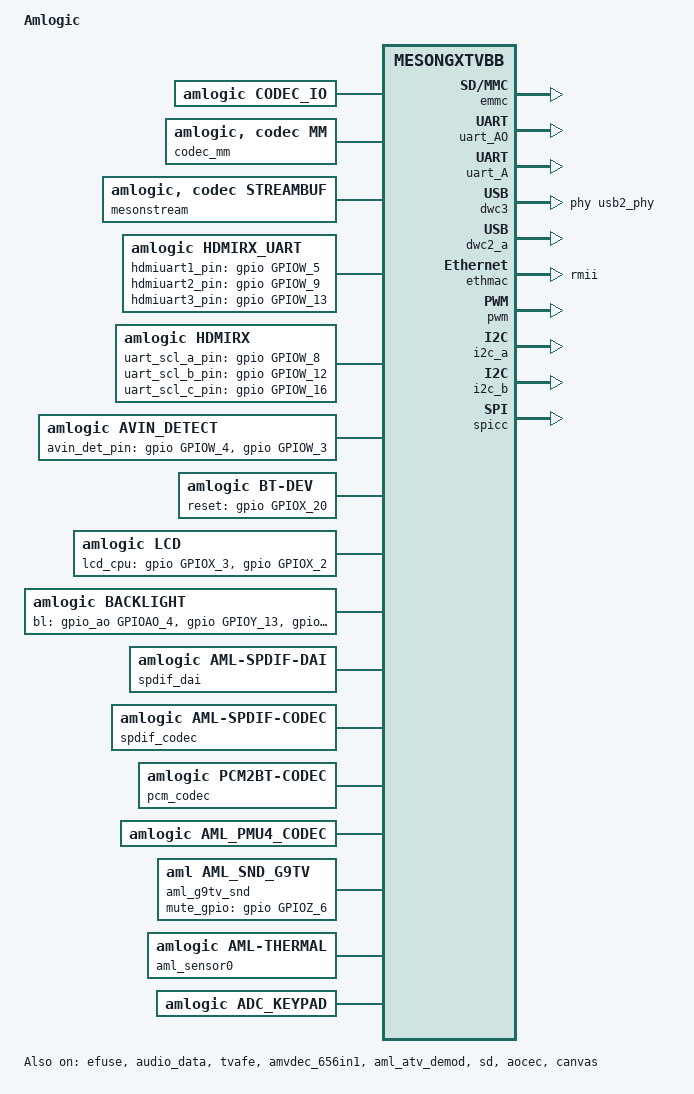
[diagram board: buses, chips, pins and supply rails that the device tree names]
/*
 * Amlogic Ltd. GXtvBaby Reference Plaform
 *
 */

/dts-v1/;

#include <dt-bindings/interrupt-controller/arm-gic.h>
#include <dt-bindings/clock/gxtvbb.h>
#include <dt-bindings/gpio/gxtvbb.h>
#include <dt-bindings/gpio/gpio.h>
#include <dt-bindings/reset/aml_gxtvbb.h>
#include "mesongxtvbb.dtsi"
#include <dt-bindings/pwm/pwm.h>
#include <dt-bindings/pwm/meson.h>

/ {
	model = "Amlogic";
	compatible = "amlogic, gxtvbb";
	interrupt-parent = <&gic>;
	#address-cells = <2>;
	#size-cells = <2>;

	aliases {
		serial0 = &uart_AO;
		serial1 = &uart_A;
	};

	memory@00000000 {
		device_type = "memory";
		linux,usable-memory = <0x0 0x1000000 0x0 0x3f000000>;
	};

	reserved-memory {
		#address-cells = <2>;
		#size-cells = <2>;
		ranges;
		/* global autoconfigured region for contiguous allocations */
		secmon_reserved:linux,secmon {
			compatible = "amlogic, aml_secmon_memory";
			reg = <0x0 0x10000000 0x0 0x200000>;
			no-map;
		};
		secos_reserved:linux,secos {
			status = "disable";
			compatible = "amlogic, aml_secos_memory";
			reg = <0x0 0x05300000 0x0 0x2000000>;
			no-map;
		};
		pstore:aml_pstore {
			compatible = "amlogic, pstore";
			reg = <0x0 0x07300000 0x0 0x100000>;
			no-map;
		};
		/*fb_reserved:linux,meson-fb {
			compatible = "amlogic, fb-memory";
			size = <0x0 0x2000000>;
			no-map;
		};*/
		/*di reserved mem*/
		di_reserved:linux,di {
			compatible = "amlogic, di-mem";
			/* buffer_size = 3552320(yuv422 8bit) | 4596800(yuv422 10bit) | 4074560(yuv422 10bit full pack mode) */
			/** 10x3552320=34M(0x22) support 8bit **/
			/** 10x44596800=44M(0x2c) support 12bit **/
			/** 10x4074560=39M(0x27) support 10bit **/
			size = <0x0 0x2c00000>;
			//no-map;
		};
		/*di CMA pool */
		//di_cma_reserved:linux,di_cma {
			//compatible = "shared-dma-pool";
			//reusable;
			/* buffer_size = 3552320(yuv422 8bit) | 44596800(yuv422 10bit) | 4074560(yuv422 10bit full pack mode) */
			/** 10x3552320=34M(0x22) support 8bit **/
			/** 10x44596800=44M(0x2c) support 12bit **/
			/** 10x4074560=39M(0x27) support 10bit **/
			//size = <0x0 0x03000000>;
			//alignment = <0x0 0x400000>;
		//};
		demod_reserved:linux,demod {
			compatible = "amlogic, demod-mem";
			size = <0x0 0x600000>; //20m
			multi-use;
			//no-map;
		};

		ion_reserved:linux,ion-dev {
			compatible = "amlogic, idev-mem";
			//size = <0x0 0x4000000>;
			/* the most significant 64M memory reserved for ion */
			reg = <0x0 0x3c000000 0x0 0x4000000>; /* for 1G memory */
			//reg = <0x0 0x5c000000 0x0 0x4000000>; /* for 1.5G memory*/
			//reg = <0x0 0x7c000000 0x0 0x4000000>; /* for 2G memory */
		};

		/*  POST PROCESS MANAGER */
		ppmgr_reserved:linux,ppmgr {
			compatible = "amlogic, ppmgr_memory";
			size = <0x0 0x0>;
			multi-use;
		};
/*
		amlvideo2_reserved:linux,amlvideo2 {
			compatible = "amlogic, amlvideo2_memory";
			size = <0x0 0x01800000>;
		};
*/
		codec_mm_cma:linux,codec_mm_cma {
			compatible = "shared-dma-pool";
			reusable;
			size = <0x0 0xc000000>;
			alignment = <0x0 0x400000>;
			linux,contiguous-region;
		};
		picdec_cma_reserved:linux,picdec {
			compatible = "shared-dma-pool";
			reusable;
			status = "disabled";
			size = <0x0 0x0>;
			alignment = <0x0 0x400000>;
			linux,contiguous-region;
		};
		/* codec shared reserved */
		codec_mm_reserved:linux,codec_mm_reserved {
			compatible = "amlogic, codec-mm-reserved";
			size = <0x0 0x4100000>;
			alignment = <0x0 0x100000>;
 			//no-map;
		};
		/*  vdin0 CMA pool */
		//vdin0_cma_reserved:linux,vdin0_cma {
		//	compatible = "shared-dma-pool";
		//	linux,phandle = <4>;
		//	reusable;
			/* 3840x2160x2x4  =64+4 M */
		//	size = <0x0 0x04400000>;
		//	alignment = <0x0 0x400000>;
		//};
		/*  vdin1 CMA pool */
		vdin1_cma_reserved:linux,vdin1_cma {
			compatible = "shared-dma-pool";
			linux,phandle = <5>;
			reusable;
			/* 1920x1080x2x4  =16+4 M */
			size = <0x0 0x01400000>;
			alignment = <0x0 0x400000>;
		};
		/*  tvafe CMA pool */
		//tvafe_cma_reserved:linux,tvafe_cma {
		//	compatible = "shared-dma-pool";
		//	linux,phandle = <6>;
		//	reusable;
			/* 5 M */
		//	size = <0x0 0x00800000>;
		//	alignment = <0x0 0x400000>;
		//};
	};

	meson-vout {
		compatible = "amlogic, meson-vout";
		dev_name = "meson-vout";
		status = "okay";
	};
	meson-fb {
		compatible = "amlogic, meson-fb";
		/*memory-region = <&fb_reserved>;*/
		dev_name = "meson-fb";
		status = "okay";
		interrupts = <0 3 1
			0 89 1>;
		interrupt-names = "viu-vsync", "rdma";
		mem_size = <0x01851000 0x00100000>; /* fb0/fb1 memory size */
		display_mode_default = "1080p60hz";
		scale_mode = <1>; /** 0:VPU free scale 1:OSD free scale 2:OSD super scale */
		// display_size_default: PAGE_ALIGN((1920*(align16(1080))/256*(256*16 + 16)+16)*3) =
		// 0x1848000 (afbc body + afbc header + 16)*3
		display_size_default = <1920 1080 1920 3240 32>;
		/*pxp_mode = <1>; /** 0:normal mode 1:pxp mode */
		logo_addr = "0x3d851000"; /*ion base + fb0 memory size for uboot logo osd1*/
	};
	ge2d {
		compatible = "amlogic, ge2d";
		dev_name = "ge2d";
		status = "okay";
		interrupts = <0 150 1>;
		interrupt-names = "ge2d";
		clocks = <&clock CLK_VAPB_0>,
			<&clock CLK_GE2D>;
		clock-names = "clk_vapb_0",
				"clk_ge2d";
		resets = <&clock GCLK_IDX_GE2D>;
		reset-names = "ge2d";
	};
	codec_io {
		compatible = "amlogic, codec_io";
		#address-cells=<2>;
		#size-cells=<2>;
		ranges;
		io_cbus_base{
			reg = <0x0 0xC0800000 0x0 0xb00000>;
		};
		io_dos_base{
			reg = <0x0 0xc8820000 0x0 0x10000>;
		};
		io_hiubus_base{
			reg = <0x0 0xc883c000 0x0 0x2000>;
		};
		io_aobus_base{
			reg = <0x0 0xc8100000 0x0 0x100000>;
		};
		io_vcbus_base{
			reg = <0x0 0xd0100000 0x0 0x40000>;
		};
		io_dmc_base{
			reg = <0x0 0xc8838000 0x0 0x2000>;
		};
	};
	codec_mm {
			compatible = "amlogic, codec, mm";
			memory-region = <&codec_mm_cma &codec_mm_reserved>;
			dev_name = "codec_mm";
			status = "okay";
	};

	mesonstream {
		compatible = "amlogic, codec, streambuf";
		dev_name = "mesonstream";
		status = "okay";
		resets = <&clock GCLK_IDX_HIU_PARSER_TOP
			&clock GCLK_IDX_VPU_INTR
			&clock GCLK_IDX_DEMUX
			&clock GCLK_IDX_DOS>;
		reset-names = "parser_top",
			"vpu_intr",
			"demux",
			"vdec";
	};

	amvideocap {
		compatible = "amlogic, amvideocap";
		dev_name = "amvideocap.0";
		status = "okay";
		max_size = <8>;//8M
	};

	ion_dev {
		compatible = "amlogic, ion_dev";
		memory-region = <&ion_reserved>;
	};

	vdec {
		compatible = "amlogic, vdec";
		dev_name = "vdec.0";
		status = "okay";
		interrupts = <0 3 1
			0 23 1
			0 32 1
			0 43 1
			0 44 1
			0 45 1>;
		interrupt-names = "vsync",
			"demux",
			"parser",
			"mailbox_0",
			"mailbox_1",
			"mailbox_2";
	};
	picdec {
		   compatible = "amlogic, picdec";
		   memory-region = <&picdec_cma_reserved>;
		   dev_name = "picdec";
		   status = "okay";
	};
	ppmgr {
		compatible = "amlogic, ppmgr";//to match of_device_id's compatible member
		memory-region = <&ppmgr_reserved>;
		dev_name = "ppmgr";
		status = "okay";
	};
	deinterlace {
		compatible = "amlogic, deinterlace";
		status = "okay";
		flag_cma = <0>;/*0:use reserved;1:use cma*/
		memory-region = <&di_reserved>;
		//memory-region = <&di_cma_reserved>;
		interrupts = <0 46 1
				0 6 1>;
		interrupt-names = "de_irq",
				"timerc";
		/* nr_size(byte) = 1920*544*2(yuv422 8bit) | 1920*544*2*12/8(yuv422 10bit) | 1920*544*2*10/8(yuv422 10bit full pack mode) */
		/* mtn_size(byte) = 1920*544/2 */
		/* count_size(byte) = 1920*544/2 */
		/* mv_size(byte) = 1920*544*2/5 */
		/* mc_size(byte) = 544*2 */
		/* buffer_size = nr_size + mtn_size + count_size + mv_size + mc_size */
		/* buffer_size = 3552320(yuv422 8bit) | 4596800(yuv422 10bit) | 4074560(yuv422 10bit full pack mode) */
		buffer-size = <4596800>;
		hw-version = <2>;
		/* reserve-iomap = "true"; */
		/* if enable nr10bit, set nr10bit-surpport to 1 */
		nr10bit-surpport = <1>;
	};
/*
	amlvideo2 {
		compatible = "amlogic, amlvideo2";
		memory-region = <&amlvideo2_reserved>;
		dev_name = "amlvideo2";
		status = "okay";
	};
*/
	vdin0 {
		compatible = "amlogic, vdin";
		/*memory-region = <&vdin0_cma_reserved>;*/
		dev_name = "vdin0";
		status = "ok";
		reserve-iomap = "true";
		flag_cma = <1>;/*1:share with codec_mm;2:cma alone*/
		/*MByte, if 10bit disable: 64M(YUV422), if 10bit enable: 64*1.5 = 96M(YUV422)
		*if support 4K2K-YUV444-10bit-WR:3840*2160*4*4 ~= 128M
		*if support 4K2K-YUV422-10bit-wr:3840*2160*3*4 ~= 96M
		*if support 4K2K-YUV422-8BIT-WR:3840*2160*2*4 ~= 64M
		*if support 1080p-YUV422-8BIT-WR:1920*1080*2*4 ~= 16M*/
		cma_size = <128>;
		interrupts = <0 83 1>;
		rdma-irq = <2>;
		clocks = <&clock CLK_FPLL_DIV5>,
			<&clock CLK_VDIN_MEAS_CLK>;
		clock-names = "fclk_div5", "cts_vdin_meas_clk";
		vdin_id = <0>;
		/*vdin write mem color depth support:
		*bit0:support 8bit
		*bit1:support 9bit
		*bit2:support 10bit
		*bit3:support 12bit*/
		tv_bit_mode = <5>;
	};
	vdin1 {
		compatible = "amlogic, vdin";
		memory-region = <&vdin1_cma_reserved>;
		dev_name = "vdin1";
		status = "ok";
		reserve-iomap = "true";
		flag_cma = <0>;/*1:share with codec_mm;0:cma alone*/
		interrupts = <0 85 1>;
		rdma-irq = <4>;
		clocks = <&clock CLK_FPLL_DIV5>,
			<&clock CLK_VDIN_MEAS_CLK>;
		clock-names = "fclk_div5", "cts_vdin_meas_clk";
		vdin_id = <1>;
		/*vdin write mem color depth support:
		*bit0:support 8bit
		*bit1:support 9bit
		*bit2:support 10bit
		*bit3:support 12bit*/
		tv_bit_mode = <1>;
	};
	hdmirx_uart {
		compatible = "amlogic, hdmirx_uart";
		status = "ok";
		pinctrl-names = "hdmirx_init_pin","hu_det_none",
				"hu_det_u1","hu_det_u2","hu_det_u3",
				"hu_det_h1","hu_det_h2","hu_det_h3",
				"hu_det_h1h2","hu_det_h1h3","hu_det_h2h3","hu_det_h1h2h3",
				"hu_det_u1_h2","hu_det_u1_h3","hu_det_u1_h2h3",
				"hu_det_u2_h1","hu_det_u2_h3","hu_det_u2_h1h3",
				"hu_det_u3_h1","hu_det_u3_h2","hu_det_u3_h1h2";
		pinctrl-0 = <&hdmirx_init_pin>;
		pinctrl-1 = <&hdmirx_init_pin &hu_hpds_gpio>;
		pinctrl-2 = <&hdmirx_init_pin &hu_hpds_gpio &u_ch1_in>;
		pinctrl-3 = <&hdmirx_init_pin &hu_hpds_gpio &u_ch2_in>;
		pinctrl-4 = <&hdmirx_init_pin &hu_hpds_gpio &u_ch3_in>;
		pinctrl-5 = <&hdmirx_init_pin &hu_hpd2_gpio &hu_hpd3_gpio>;
		pinctrl-6 = <&hdmirx_init_pin &hu_hpd1_gpio &hu_hpd3_gpio>;
		pinctrl-7 = <&hdmirx_init_pin &hu_hpd1_gpio &hu_hpd2_gpio>;
		pinctrl-8 = <&hdmirx_init_pin &hu_hpd3_gpio>;
		pinctrl-9 = <&hdmirx_init_pin &hu_hpd2_gpio>;
		pinctrl-10 = <&hdmirx_init_pin &hu_hpd1_gpio>;
		pinctrl-11 = <&hdmirx_init_pin &hu_uart_init>;
		pinctrl-12 = <&hdmirx_init_pin &hu_hpd1_gpio &hu_hpd3_gpio &u_ch1_in>;
		pinctrl-13 = <&hdmirx_init_pin &hu_hpd1_gpio &hu_hpd2_gpio &u_ch1_in>;
		pinctrl-14 = <&hdmirx_init_pin &hu_hpd1_gpio &u_ch1_in>;
		pinctrl-15 = <&hdmirx_init_pin &hu_hpd2_gpio &hu_hpd3_gpio &u_ch2_in>;
		pinctrl-16 = <&hdmirx_init_pin &hu_hpd1_gpio &hu_hpd2_gpio &u_ch2_in>;
		pinctrl-17 = <&hdmirx_init_pin &hu_hpd2_gpio &u_ch2_in>;
		pinctrl-18 = <&hdmirx_init_pin &hu_hpd2_gpio &hu_hpd3_gpio &u_ch3_in>;
		pinctrl-19 = <&hdmirx_init_pin &hu_hpd1_gpio &hu_hpd3_gpio &u_ch3_in>;
		pinctrl-20 = <&hdmirx_init_pin &hu_hpd3_gpio &u_ch3_in>;
		hdmiuart1_pin =  <&gpio       GPIOW_5       GPIO_ACTIVE_HIGH>;
		hdmiuart2_pin =  <&gpio       GPIOW_9       GPIO_ACTIVE_HIGH>;
		hdmiuart3_pin =  <&gpio       GPIOW_13      GPIO_ACTIVE_HIGH>;
		hdmiuart_use_num = <7>;/*0:dont use. 1:use num1. 2:use num2. 4:use num3*/
	};

	hdmirx {
		compatible = "amlogic, hdmirx";
		dev_name = "hdmirx";
		status = "ok";
		pinctrl-names = "hdmirx_pins","hu_det_none",
				"hu_det_uart0","hu_det_uart1","hu_det_uart2";
		pinctrl-0 = <&hdmirx_pins>;
		pinctrl-1 = <&hu_det_none>;
		pinctrl-2 = <&hdmirx_pins &cha_uart_in>;
		pinctrl-3 = <&hdmirx_pins &chb_uart_in>;
		pinctrl-4 = <&hdmirx_pins &chc_uart_in>;
		rx_port_maps = <0x3120>;
		hdmiuart_share_cfg = <0>;
		repeat = <0>;
		interrupts = <0 56 1>;
		hdmirx_addr_port = <0xda83e000>;
		hdmirx_data_port = <0xda83e004>;
		hdmirx_ctrl_port = <0xda83e008>;
		clocks = <&clock CLK_HDMIRX_MODET_CLK>,
			<&clock CLK_HDMIRX_CFG_CLK>,
			<&clock CLK_HDMIRX_ACR_REF_CLK>,
			<&clock CLK_HDMIRX_AUDMEAS_CLK>,
			<&clock CLK_XTAL>,
			<&clock CLK_FPLL_DIV5>;
		clock-names = "hdmirx_modet_clk",
			"hdmirx_cfg_clk",
			"hdmirx_acr_ref_clk",
			"hdmirx_audmeas_clk",
			"xtal",
			"fclk_div5";
		hdmirx_id = <0>;
		en_4k_2_2k = <0>;
		uart_scl_a_pin =  <&gpio       GPIOW_8       GPIO_ACTIVE_HIGH>;
		uart_scl_b_pin =  <&gpio       GPIOW_12      GPIO_ACTIVE_HIGH>;
		uart_scl_c_pin =  <&gpio       GPIOW_16      GPIO_ACTIVE_HIGH>;
 	};
	tvafe {
		compatible = "amlogic, tvafe";
		/*memory-region = <&tvafe_cma_reserved>;*/
		dev_name = "tvafe";
		status = "ok";
		flag_cma = <1>;/*1:share with codec_mm;0:cma alone*/
		cma_size = <5>;/*MByte*/
		reg = <0x0 0xc8842000 0x0 0x2000>;
		reserve-iomap = "true";
		tvafe_id = <0>;
		pinctrl-names = "default";
		tvafe_pin_mux = < /*!!particular sequence, no more and no less!!!*/
                        2       /*// TVAFE_CVBS_IN1,  //CVBS_IN0 = 0,*/
                        1       /*// TVAFE_CVBS_IN0,    //CVBS_IN1,*/
                        3       /*// TVAFE_CVBS_IN2,  //CVBS_IN2*/
                        4       /*// TVAFE_CVBS_IN3,    //CVBS_IN3,*/
		>;
	};
	avin_detect {
		compatible = "amlogic, avin_detect";
		status = "okay";
		avin_device_num = <2>;
		interrupts = <0 65 1
					  0 66 1>;
		pinctrl-names = "avin_gpio_disable_pullup";
		pinctrl-0 = <&avin_gpio_disable_pull>;
		avin_det_pin =  <&gpio       GPIOW_4       GPIO_ACTIVE_HIGH>,
						<&gpio       GPIOW_3       GPIO_ACTIVE_HIGH>;
		detect_interval_length = <100>;
		set_detect_times = <5>;
		set_fault_tolerance = <1>;
	};
	amvdec_656in1 {
		compatible = "amlogic, amvdec_656in";
		dev_name = "amvdec_656in1";
		status = "ok";
		reg = <0x0 0xd0050000 0x0 0x7c>;
		clocks = <&clock CLK_FPLL_DIV2>,
			<&clock CLK_BT656_CLK1>;
		clock-names = "fclk_div2", "cts_bt656_clk1";
		bt656_id = <1>;
	};
	dvb {
		compatible = "amlogic, dvb";
		dev_name = "dvb";
		status = "okay";
		/*"parallel","serial","disable"*/
		ts2 = "parallel";
		ts2_control = <0>;
		ts2_invert = <0>;
		resets = <&clock GCLK_IDX_DEMUX
				&clock GCLK_IDX_ASYNC_FIFO
				&clock GCLK_IDX_AHB_ARB0
				&clock GCLK_IDX_HIU_PARSER_TOP>;
		reset-names = "demux", "asyncfifo", "ahbarb0", "uparsertop";
	};
	dvbfe {
		compatible = "amlogic, dvbfe";
		dev_name = "dvbfe";
		status = "okay";
		dtv_demod0 = "AMLDEMOD";
		fe0_dtv_demod = <0>;
		fe0_ts = <2>;
		fe0_dev = <0>;
		dtv_demod0_mem = <0>;
		dtv_demod0_spectrum = <1>;
		memory-region = <&demod_reserved>;
		tuner0 = "r840_tuner";
		tuner0_i2c_adap_id = <1>;
		tuner0_i2c_addr = <0x74>;
		//tuner0_reset_value = <0>;
		//tuner0_reset_gpio =  "GPIOY_10" ;  /*GPIOX_8   76*/
		fe0_tuner = <0>;
		atv_demod0 = "aml_atv_demod";
		fe0_atv_demod = <0>;
	};
	aml_atv_demod {
		compatible = "amlogic, aml_atv_demod";
		dev_name = "aml_atv_demod";
		status = "okay";
		pinctrl-names="atvdemod_agc";
		pinctrl-0=<&atvdemod_agc>;
		reg = <0x0 0xc8840000 0x0 0x2000>;
		reg_23cf = <0x88188832>;/*default:0x88188832;r840 on haier:0x48188832*/
		audio_gain_val = <1024>; /*haier need this*/
		video_gain_val = <0x5C8808C1>;
	};
	amlvecm {
		compatible = "amlogic, vecm";
		dev_name = "aml_vecm";
		status = "okay";
		gamma_en = <1>;/*1:enabel ;0:disable*/
		wb_en = <1>;/*1:enabel ;0:disable*/
		cm_en = <1>;/*1:enabel ;0:disable*/
	};

	amvenc_avc{
		compatible = "amlogic, amvenc_avc";
		//memory-region = <&amvenc_avc_reserved>;
		//memory-region = <&avc_cma_reserved>;
		dev_name = "amvenc_avc";
		status = "okay";
		interrupts = <0 45 1>;
		interrupt-names = "mailbox_2";
	};



	vpu {
		compatible = "amlogic, vpu";
		dev_name = "vpu";
		status = "ok";
		clk_level = <7>;
		/**	0: 100.0M    1: 166.7M    2: 200.0M
			3: 250.0M    4: 333.3M    5: 400.0M
			6: 500.0M    7: 666.7M */
	};
	bt-dev{
		compatible = "amlogic, bt-dev";
		dev_name = "bt-dev";
		status = "ok";
		gpio_reset = <&gpio       GPIOX_20       GPIO_ACTIVE_HIGH>;
	};
	rtc {
		compatible = "amlogic, aml_vrtc";
		alarm_reg_addr = <0xc81000a8>;
		timer_e_addr = <0xc1109988>;
		init_date = "2015/01/01";
		status = "okay";
	};
	emmc{
		compatible = "amlogic, aml_sd_emmc";
		dev_name = "aml_newsd.0";
		status = "okay";
		reg = <0x0 0xd0074000 0x0 0x2000>;
		interrupts = <	0 218 1>;
		pinctrl-names = "emmc_clk_cmd_pins", "emmc_all_pins";
		pinctrl-0 = <&emmc_clk_cmd_pins>;
		pinctrl-1 = <&emmc_all_pins>;
		emmc{
			status = "okay";
			pinname = "emmc";
			ocr_avail = <0x200080>;          /**VDD voltage 3.3 ~ 3.4 */
			caps = "MMC_CAP_8_BIT_DATA","MMC_CAP_MMC_HIGHSPEED",
				 "MMC_CAP_SD_HIGHSPEED", "MMC_CAP_NONREMOVABLE", "MMC_CAP_1_8V_DDR",
				 "MMC_CAP_ERASE", "MMC_CAP_HW_RESET", "MMC_CAP_CMD23";
			caps2 = "MMC_CAP2_HS200";
			f_min = <300000>;
			f_max = <100000000>;
			tx_phase = <1>;
			max_req_size = <0x20000>;          /**256KB*/
			//            gpio_dat3 = "BOOT_3"
			gpio_dat3 = <&gpio       BOOT_3      GPIO_ACTIVE_HIGH>;
			hw_reset =  <&gpio       BOOT_9      GPIO_ACTIVE_HIGH>;
			card_type = <1>; /* 1:mmc card(include eMMC), 2:sd card(include tSD), */
		};
	};
    sd{
        compatible = "amlogic, aml_sd_emmc";
        dev_name = "aml_newsd.0";
        status = "okay";
        reg = <0x0 0xd0072000 0x0 0x2000>;
        interrupts = <	0 217 1
        				0 67 1
        				0 69 1>;
        pinctrl-names = "sd_clk_cmd_pins", "sd_all_pins";
        pinctrl-0 = <&sd_clk_cmd_pins>;
        pinctrl-1 = <&sd_all_pins>;
		sd{
	   		status = "okay";
	   		pinname = "sd";
	   		ocr_avail = <0x00200080>; // 3.3:0x200000, 1.8+3.3:0x00200080
	   		caps = "MMC_CAP_4_BIT_DATA","MMC_CAP_MMC_HIGHSPEED",
					"MMC_CAP_SD_HIGHSPEED";
	   				//,"MMC_CAP_UHS_SDR12",
	   				//"MMC_CAP_UHS_SDR25","MMC_CAP_UHS_SDR50",
	   				//"MMC_CAP_UHS_SDR104","MMC_CAP_NONREMOVABLE";
	   		f_min = <300000>;
	   		f_max = <100000000>;
	   		max_req_size = <0x20000>;          /**128KB*/
			gpio_dat3 = <&gpio       CARD_4       GPIO_ACTIVE_HIGH>;
			jtag_pin =  <&gpio       CARD_0       GPIO_ACTIVE_HIGH>;
			gpio_cd =  <&gpio       CARD_6       GPIO_ACTIVE_HIGH>;
			irq_in = <3>;
			irq_out = <5>;
	   		card_type = <5>; /* 0:unknown, 1:mmc card(include eMMC), 2:sd card(include tSD), 3:sdio device(ie:sdio-wifi), 4:SD combo (IO+mem) card, 5:NON sdio device(means sd/mmc card), other:reserved */
		};
    };

	nand{
		compatible = "amlogic, aml_nand";
		dev_name = "nand";
		status = "disabled";
		reg = <0x0 0xd0074800 0x0 0x200>;
		interrupts = <	0 34 1 >;
		pinctrl-names = "nand_rb_mod","nand_norb_mod", "nand_cs_pins_only";
		pinctrl-0 = <&conf_nand_pulldown &conf_nand_pullup &all_nand_pins>;
		pinctrl-1 = <&conf_nand_pulldown &conf_nand_pullup &all_nand_pins>;
		pinctrl-2 = <&nand_cs_pins>;
		device_id = <0>;
		plat-names = "nandnormal";
		plat-num = <1>;
		plat-part-0 = <&normal>;
		normal: normal{
			enable_pad ="ce0","ce1","ce2","ce3";
			busy_pad = "rb0";
		};
	};
	partitions: partitions{
        parts = <12>;
		part-0 = <&logo>;
		part-1 = <&recovery>;
		part-2 = <&param>;
		part-3 = <&tee>;
		part-4 = <&crypt>;
		part-5 = <&misc>;
		part-6 = <&instaboot>;
		part-7 = <&boot>;
		part-8 = <&system>;
		part-9 = <&cache>;
		part-10 = <&cri_data>;
		part-11 = <&data>;

		logo:logo{
			pname = "logo";
			size = <0x0 0x2000000>;
			mask = <1>;
		};
		recovery:recovery{
			pname = "recovery";
			size = <0x0 0x2000000>;
			mask = <1>;
		};
		param:param{
			pname = "param";
			size = <0x0 0x8000000>;
			mask = <2>;
		};
		tee:tee{
			pname = "tee";
			size = <0x0 0x800000>;
			mask = <1>;
		};
		crypt:crypt{
			pname = "crypt";
			size = <0x0 0x2000000>;
			mask = <1>;
		};
		misc:misc{
			pname = "misc";
			size = <0x0 0x2000000>;
			mask = <1>;
		};
		instaboot:instaboot{
			pname = "instaboot";
			size = <0x0 0x20000000>;
			mask = <1>;
		};
		boot:boot
		{
			pname = "boot";
			size = <0x0 0x2000000>;
			mask = <1>;
		};
		system:system
		{
			pname = "system";
			size = <0x0 0x40000000>;
			mask = <1>;
		};
		cache:cache
		{
			pname = "cache";
			size = <0x0 0x20000000>;
			mask = <2>;
		};
		cri_data:cri_data
		{
			pname = "cri_data";
			size = <0x0 0x1000000>;
			mask = <2>;
		};
		data:data
		{
			pname = "data";
			size = <0xffffffff 0xffffffff>;
			mask = <4>;
		};
	};
	unifykey{
		compatible = "amlogic, unifykey";
		status = "ok";

		unifykey-num = <14>;
		unifykey-index-0 = <&keysn_0>;
		unifykey-index-1 = <&keysn_1>;
		unifykey-index-2 = <&keysn_2>;
		unifykey-index-3 = <&keysn_3>;
		unifykey-index-4 = <&keysn_4>;
		unifykey-index-5 = <&keysn_5>;
		unifykey-index-6 = <&keysn_6>;
		unifykey-index-7 = <&keysn_7>;
		unifykey-index-8 = <&keysn_8>;
		unifykey-index-9 = <&keysn_9>;
		unifykey-index-10= <&keysn_10>;
		unifykey-index-11 = <&keysn_11>;
		unifykey-index-12 = <&keysn_12>;
		unifykey-index-13 = <&keysn_13>;

                keysn_0: key_0{
			key-name = "usid";
			key-device = "normal";
			key-permit = "read","write","del";
		};
		keysn_1:key_1{
			key-name = "mac";
                        key-device  = "normal";
			key-permit = "read","write","del";
		};
		keysn_2:key_2{
                        key-name = "hdcp";
			key-device = "secure";
                        key-type  = "sha1";
			key-permit = "read","write","del";
		};
		keysn_3:key_3{
			key-name = "secure_boot_set";
			key-device = "efuse";
			key-permit = "write";
		};
		keysn_4:key_4{
			key-name = "mac_bt";
			key-device = "normal";
			key-permit = "read","write","del";
                        key-type  = "mac";
		};
		keysn_5:key_5{
			key-name = "mac_wifi";
			key-device = "normal";
			key-permit = "read","write","del";
                        key-type  = "mac";
		};
		keysn_6:key_6{
			key-name = "hdcp2_tx";
			key-device = "normal";
			key-permit = "read","write","del";
		};
		keysn_7:key_7{
			key-name = "hdcp2_rx";
			key-device = "normal";
			key-permit = "read","write","del";
		};
		keysn_8:key_8{
			key-name = "widevinekeybox";
			key-device = "secure";
			key-permit = "read","write","del";
		};
		keysn_9:key_9{
			key-name = "deviceid";
			key-device = "normal";
			key-permit = "read","write","del";
		};
		keysn_10:key_10{
			key-name = "hdcp22_fw_private";
			key-device = "secure";
			key-permit = "read","write","del";
		};
		keysn_11:key_11{
			key-name = "hdcp22_rx_private";
			key-device = "secure";
			key-permit = "read","write","del";
		};
		keysn_12:key_12{
			key-name = "hdcp22_rx_fw";
			key-device = "normal";
			key-permit = "read","write","del";
		};
		keysn_13:key_13{
			key-name = "hdcp14_rx";
			key-device = "normal";
			key-type  = "sha1";
			key-permit = "read","write","del";
		};
        };//End unifykey
	ampmu4 {
		compatible = "amlogic, pmu4_prober";
		#address-cells = <1>;
		#size-cells = <0>;

		pmu4 {
			compatible = "amlogic, pmu4";
			sub_type = "aml_pmu4";
			i2c_bus = "i2c_bus_b";
			reg = <0x35>;
			use_24m_clock = <0x1>;
			status = "okay";
		};
	};

	amhdmitx: amhdmitx{
		compatible = "amlogic, amhdmitx";
		dev_name = "amhdmitx";
		status = "disabled";
		pinctrl-names="hdmitx_hpd", "hdmitx_ddc";
		pinctrl-0=<&hdmitx_hpd>;
		pinctrl-1=<&hdmitx_ddc>;
		/* HPD, 57 + 32 = 89; CEC, 151 + 32 = 183*/
		interrupts = <0 57 1>;
		interrupt-names = "hdmitx_hpd";
		clocks = <&clock CLK_HDMITX_SYS &clock CLK_HDMITX_ENCP
			&clock CLK_HDMITX_ENCI &clock CLK_HDMITX_PIXEL
			&clock CLK_HDMITX_PHY &clock CLK_VID>;
		clock-names = "hdmitx_clk_sys", "hdmitx_clk_encp", "hdmitx_clk_enci",
			"hdmitx_clk_pixel", "hdmitx_clk_phy", "hdmitx_clk_vid";
	};

	aocec: aocec{
		compatible = "amlogic, amlogic-aocec";
		device_name = "aocec";
		status = "okay";
		vendor_name = "Amlogic"; /* Max Chars: 8     */
		vendor_id = <0x000000>; /* Refer to http://standards.ieee.org/develop/regauth/oui/oui.txt   */
		product_desc = "GXTVBB"; /* Max Chars: 16    */
		cec_osd_string = "AML_TV"; /* Max Chars: 14    */
		port_num = <3>;
		ee_cec;
		arc_port_mask = <0x2>;
		interrupts = <0 56 1>;
		interrupt-names = "hdmi_eecec";
		pinctrl-names = "hdmitx_eecec";
		pinctrl-0=<&hdmitx_eecec>;
		reg = <0x0 0xc810023c 0x0 0x4
		       0x0 0xc8100000 0x0 0x200
		       0x0 0xda83e000 0x0 0x10
		       0x0 0xc883c000 0x0 0x400>;
	};

	tvout {
		compatible = "amlogic, tvout";
		dev_name = "tvout";
		status = "disabled";
	};

	uart_AO: serial@c81004c0 {
		compatible = "amlogic, meson-uart";
		reg = <0x0 0xc81004c0 0x0 0x14>;
		interrupts = <0 193 1>;
		status = "okay";
		clocks = <&clock CLK_XTAL>;
		clock-names = "clk_uart";
		fifosize = < 64 >;
		pinctrl-names = "default";
		pinctrl-0 = <&ao_a_uart_pins>;
		support-sysrq = <0>;	/* 0 not support , 1 support */
	};

	uart_A: serial@c11084c0 {
		compatible = "amlogic, meson-uart";
		reg = <0x0 0xc11084c0 0x0 0x14>;
		interrupts = <0 26 1>;
		status = "okay";
		clocks = <&clock CLK_XTAL>;
		clock-names = "clk_uart";
		fifosize = < 128 >;
		pinctrl-names = "default";
		pinctrl-0 = <&a_uart_pins>;
	};

       dwc3: dwc3@c9000000 {
               compatible = "synopsys, dwc3";
               reg = <0x0 0xc9000000 0x0 0x100000>;
               interrupts = <0 30 4>;
               usb-phy = <&usb2_phy>, <&usb3_phy>;
               cpu-type = "gxbabytv";
               clock-src = "usb3.0";
       };

       usb2_phy: usb2phy@d007800 {
               compatible = "amlogic, amlogic-usb2";
               portnum = <4>;
               reg = <0x0 0xd0078000 0x0 0x80>;
       };

       usb3_phy: usb3phy@d0078080 {
               compatible = "amlogic, amlogic-usb3";
               portnum = <1>;
               reg = <0x0 0xd0078080 0x0 0x20>;
       };

	dwc2_a {
                compatible = "amlogic,dwc2";
                device_name = "dwc2_a";
                reg = <0x0 0xc9100000 0x0 0x40000>;
                interrupts = <0 31 4>;
                status = "okay";
                pl-periph-id = <0>; /** lm name */
                clock-src = "usb0"; /** clock src */
                port-id = <0>;  /** ref to mach/usb.h */
                port-type = <2>;        /** 0: otg, 1: host, 2: slave */
                port-speed = <0>; /** 0: default, high, 1: full */
                port-config = <0>; /** 0: default */
                port-dma = <0>; /** 0: default, 1: single, 2: incr, 3: incr4, 4: incr8, 5: incr16, 6: disable*/
                port-id-mode = <0>; /** 0: hardware, 1: sw_host, 2: sw_slave*/
                usb-fifo = <512>;
                cpu-type = "gxtvbaby";
                controller-type = <1>; /** 0: normal, 1: otg+dwc3*/
                phy-reg = <0xd0078000>;
                phy-reg-size = <0xa0>;
                resets = <&clock GCLK_IDX_USB_GENERAL
			&clock GCLK_IDX_MISC_USB1_TO_DDR
			&clock GCLK_IDX_USB1>;
                reset-names = "usb_general",
						"usb1",
						"usb1_to_ddr";
       };

	canvas{
		compatible = "amlogic, meson, canvas";
		dev_name = "amlogic-canvas";
		status = "ok";
		reg = <0x0 0xc8838000 0x0 0x400>;
	};

	rdma{
		compatible = "amlogic, meson, rdma";
		dev_name = "amlogic-rdma";
		status = "ok";
		interrupts = <0 89 1>;
		interrupt-names = "rdma";
	};

	sysled {
		compatible = "amlogic, sysled";
		dev_name = "sysled";
		status = "disable";
		led_gpio = <&gpio_ao GPIOAO_11 GPIO_ACTIVE_LOW>;
	};

	pwmled {
		compatible = "amlogic, pwmled";
		dev_name = "pwmled";
		status = "okay";
		pwm = <6>; /* pwm_ao_a */
		polarity = <1>; /* 0-normal 1-inversed */
		max_brightness = <255>;
		pinctrl-names = "pwm_ao_a_pins";
		pinctrl-0 = <&pwm_ao_a_pins>;
		/* led timer data */
		expires = <400>; /* ms */
		expires_count = <8>;
	};

	lcd{
		compatible = "amlogic, lcd";
		dev_name = "lcd";
		mode = "tv";
		status = "okay";
		fr_auto_policy = <1>; /* 0=disable, 1=60/50hz, 2=60/50/48hz */
		key_valid = <0>;
		resets = <&clock GCLK_IDX_VCLK2_ENCL &clock GCLK_IDX_VCLK2_VENCL>;
		reset-names = "encl","vencl";
		interrupts = <0 78 1 0 3 1>;
		interrupt-names = "vbyone","vbyone_vsync";
		pinctrl-names = "vbyone";
		pinctrl-0 = <&lcd_vbyone_pins>;

		/* power type:(0=cpu_gpio, 1=pmu_gpio, 2=signal, 3=extern, 0xff=ending) */
		/* power index:(point gpios_index, or extern_index, 0xff=invalid) */
		/* power value:(0=output low, 1=output high, 2=input) */
		/* power delay:(unit in ms) */
		lcd_cpu-gpios = <&gpio GPIOX_3 GPIO_ACTIVE_HIGH
				&gpio GPIOX_2 GPIO_ACTIVE_HIGH>;
		lcd_cpu_gpio_names = "GPIOX_3","GPIOX_2";

		lvds_0{
			model_name = "1080p-vfreq";
			interface = "lvds"; /* lcd_interface(lvds, vbyone) */
			basic_setting = <1920 1080 2200 1125 8 16 9>; /* h_active, v_active, h_period, v_period, lcd_bits, screen_widht, screen_height */
			range_setting = <2060 2650 1100 1480 120000000 160000000>; /* h_period_min,max, v_period_min,max, pclk_min,max */
			lcd_timing = <44 148 0 5 30 0>; /* hs_width, hs_bp, hs_pol, vs_width, vs_bp, vs_pol */
			clk_attr = <2 0 1 0>; /* fr_adj_type(0=clock, 1=htotal, 2=vtotal, 3=auto range), clk_ss_level, clk_auto_generate, pixel_clk(unit in Hz) */
			lvds_attr = <1 1 0 0 0>; /* lvds_repack, dual_port, pn_swap, port_swap, lane_reverse */
			phy_attr=<3 0 0 0>; /* vswing_level, preemphasis_level, lvds_clk_vswing_level, lvds_clk_preem_level */
			power_on_step = <0 0 1 20 /* panel power on */
					2 0 0 0   /* signal enable */
					0xff 0 0 0>; /* type, index, value, delay */
			power_off_step = <2 0 0 20 /* signal disable */
					0 0 0 100  /* panel power off */
					0xff 0 0 0>; /* type, index, value, delay */
			backlight_index = <0>;
		};
		lvds_1{
			model_name = "1080p-pclk";
			interface = "lvds"; /* lcd_interface(lvds, vbyone) */
			basic_setting = <1920 1080 2200 1125 8 16 9>; /* h_active, v_active, h_period, v_period, lcd_bits, screen_widht, screen_height */
			range_setting = <2080 2720 1100 1380 133940000 156000000>; /* h_period_min,max, v_period_min,max, pclk_min,max */
			lcd_timing = <44 148 0 5 30 0>; /* hs_width, hs_bp, hs_pol, vs_width, vs_bp, vs_pol */
			clk_attr = <0 0 1 0>; /* fr_adj_type(0=clock, 1=htotal, 2=vtotal, 3=auto range), clk_ss_level, clk_auto_generate, pixel_clk(unit in Hz) */
			lvds_attr = <1 1 0 0 0>; /* lvds_repack, dual_port, pn_swap, port_swap, lane_reverse */
			phy_attr=<3 0 0 0>; /* vswing_level, preemphasis_level, lvds_clk_vswing_level, lvds_clk_preem_level */
			power_on_step = <0 0 1 20 /* panel power on */
					2 0 0 0   /* signal enable */
					0xff 0 0 0>; /* type, index, value, delay */
			power_off_step = <2 0 0 20 /* signal disable */
					0 0 0 100  /* panel power off */
					0xff 0 0 0>; /* type, index, value, delay */
			backlight_index = <0>;
		};
		lvds_2{
			model_name = "1080p-hfreq";
			interface = "lvds"; /* lcd_interface(lvds, vbyone) */
			basic_setting = <1920 1080 2200 1125 8 16 9>; /* h_active, v_active, h_period, v_period, lcd_bits, screen_widht, screen_height */
			range_setting = <2080 2720 1100 1380 133940000 156000000>; /* h_period_min,max, v_period_min,max, pclk_min,max */
			lcd_timing = <44 148 0 5 30 0>; /* hs_width, hs_bp, hs_pol, vs_width, vs_bp, vs_pol */
			clk_attr = <1 0 1 0>; /* fr_adj_type(0=clock, 1=htotal, 2=vtotal, 3=auto range), clk_ss_level, clk_auto_generate, pixel_clk(unit in Hz) */
			lvds_attr = <1 1 0 0 0>; /* lvds_repack, dual_port, pn_swap, port_swap, lane_reverse */
			phy_attr=<3 0 0 0>; /* vswing_level, preemphasis_level, lvds_clk_vswing_level, lvds_clk_preem_level */
			power_on_step = <0 0 1 20 /* panel power on */
					2 0 0 0   /* signal enable */
					0xff 0 0 0>; /* type, index, value, delay */
			power_off_step = <2 0 0 20 /* signal disable */
					0 0 0 100  /* panel power off */
					0xff 0 0 0>; /* type, index, value, delay */
			backlight_index = <0>;
		};

		vbyone_0{
			model_name = "public";
			interface = "vbyone"; /* lcd_interface(lvds, vbyone) */
			basic_setting = <3840 2160 4400 2250 10 16 9>; /* h_active, v_active, h_period, v_period, lcd_bits, screen_widht, screen_height */
			range_setting = <4340 4700 2200 2850 480000000 614000000>; /* h_period_min,max, v_period_min,max, pclk_min,max */
			lcd_timing = <33 477 0 6 65 0>; /* hs_width, hs_bp, hs_pol, vs_width, vs_bp, vs_pol */
			clk_attr = <0 0 1 0>; /* fr_adj_type(0=clock, 1=htotal, 2=vtotal, 3=auto range), clk_ss_level, clk_auto_generate, pixel_clk(unit in Hz) */
			vbyone_attr = <8 2 4 4>; /* lane_count, region_num, byte_mode, color_fmt */
			vbyone_intr_enable = <1 1>; /* vbyone_intr_enable, vbyone_vsync_intr_enable */
			phy_attr=<3 0>; /* vswing_level, preemphasis_level */
			power_on_step = <0 0 1 50 /* panel power on */
					2 0 0 200   /* signal enable */
					0xff 0 0 0>; /* type, index, value, delay */
			power_off_step = <2 0 0 50 /* signal disable */
					0 0 0 100  /* panel power off */
					0xff 0 0 0>; /* type, index, value, delay */
			backlight_index = <0>;
		};

		vbyone_1{
			model_name = "LG_RDL550WY";
			interface = "vbyone"; /* lcd_interface(lvds, vbyone) */
			basic_setting = <3840 2160 4400 2250 10 16 9>; /* h_active, v_active, h_period, v_period, lcd_bits, screen_widht, screen_height */
			range_setting = <4240 4800 2200 2760 480000000 624000000>; /* h_period_min,max, v_period_min,max, pclk_min,max */
			lcd_timing = <33 477 0 6 65 0>; /* hs_width, hs_bp, hs_pol, vs_width, vs_bp, vs_pol */
			clk_attr = <2 0 1 0>; /* fr_adj_type(0=clock, 1=htotal, 2=vtotal, 3=auto range), clk_ss_level, clk_auto_generate, pixel_clk(unit in Hz) */
			vbyone_attr = <8 2 4 4>; /* lane_count, region_num, byte_mode, color_fmt */
			vbyone_intr_enable = <1 1>; /* vbyone_intr_enable, vbyone_vsync_intr_enable */
			phy_attr=<3 0>; /* vswing_level, preemphasis_level */
			power_on_step = <0 0 1 50 /* panel power on */
					2 0 0 0   /* signal enable */
					0xff 0 0 0>; /* type, index, value, delay */
			power_off_step = <2 0 0 50 /* signal disable */
					0 0 0 100  /* panel power off */
					0xff 0 0 0>; /* type, index, value, delay */
			backlight_index = <0>;
		};

		vbyone_2{
			model_name = "INL_V580DJ2";
			interface = "vbyone"; /* lcd_interface(lvds, vbyone) */
			basic_setting = <3840 2160 4400 2250 10 16 9>; /* h_active, v_active, h_period, v_period, lcd_bits, screen_widht, screen_height */
			range_setting = <4240 4800 2200 2790 552000000 632000000>; /* h_period_min,max, v_period_min,max, pclk_min,max */
			lcd_timing = <33 477 0 6 65 0>; /* hs_width, hs_bp, hs_pol, vs_width, vs_bp, vs_pol */
			clk_attr = <2 0 1 0>; /* fr_adj_type(0=clock, 1=htotal, 2=vtotal, 3=auto range), clk_ss_level, clk_auto_generate, pixel_clk(unit in Hz) */
			vbyone_attr = <8 1 4 4>; /* lane_count, region_num, byte_mode, color_fmt */
			vbyone_intr_enable = <1 1>; /* vbyone_intr_enable, vbyone_vsync_intr_enable */
			phy_attr=<3 0>; /* vswing_level, preemphasis_level */
			power_on_step = <0 0 1 50 /* panel power on */
					2 0 0 0   /* signal enable */
					0xff 0 0 0>; /* type, index, value, delay */
			power_off_step = <2 0 0 50 /* signal disable */
					0 0 0 100  /* panel power off */
					0xff 0 0 0>; /* type, index, value, delay */
			backlight_index = <0>;
		};

		vbyone_3{
			model_name = "BOE_HV550QU2";
			interface = "vbyone"; /* lcd_interface(lvds, vbyone) */
			basic_setting = <3840 2160 4400 2250 10 16 9>; /* h_active, v_active, h_period, v_period, lcd_bits, screen_widht, screen_height */
			range_setting = <4240 4800 2200 2760 560000000 624000000>; /* h_period_min,max, v_period_min,max, pclk_min,max */
			lcd_timing = <33 477 1 6 65 0>; /* hs_width, hs_bp, hs_pol, vs_width, vs_bp, vs_pol */
			clk_attr = <2 0 1 0>; /* fr_adj_type(0=clock, 1=htotal, 2=vtotal, 3=auto range), clk_ss_level, clk_auto_generate, pixel_clk(unit in Hz) */
			vbyone_attr = <8 2 4 4>; /* lane_count, region_num, byte_mode, color_fmt */
			vbyone_intr_enable = <1 1>; /* vbyone_intr_enable, vbyone_vsync_intr_enable */
			phy_attr=<3 0>; /* vswing_level, preemphasis_level */
			power_on_step = <0 0 1 20 /* panel power on */
					0 1 0 10  /* 3d_enable=0 */
					2 0 0 0   /* signal enable */
					0xff 0 0 0>; /* type, index, value, delay */
			power_off_step = <2 0 0 30 /* signal disable */
					0 1 2 0    /* 3d_enable pin reset to input */
					0 0 0 100  /* panel power off */
					0xff 0 0 0>; /* type, index, value, delay */
			backlight_index = <0>;
		};
	};

	lcd_extern{
		compatible = "amlogic, lcd_extern";
		dev_name = "lcd_extern";
		status = "okay";
		key_valid = <0>;

		extern_0{
			index = <0>;
			extern_name = "ext_default";
			status = "disabled";
			type = <0>; /* 0=i2c, 1=spi, 2=mipi */
			i2c_address = <0x1c>; /* 7bit i2c address */
			i2c_second_address = <0xff>; /* 7bit i2c address, 0xff for none */
			i2c_bus = "i2c_bus_d";
			cmd_size = <9>;
			/* init on/off: (type, value..., delay), must match cmd_size for every group */
			/* type: 0x00=cmd(bit[3:0]=1 for second_addr), 0x10=gpio, 0xff=ending*/
			/* value: i2c or spi cmd, or gpio index & level, fill 0x0 for no use */
			/* delay: unit ms */
			init_on = <0x00 0x20 0x01 0x02 0x00 0x40 0xFF 0x00 0x00
				0x00 0x80 0x02 0x00 0x40 0x62 0x51 0x73 0x00
				0x00 0x61 0x06 0x00 0x00 0x00 0x00 0x00 0x00
				0x00 0xC1 0x05 0x0F 0x00 0x08 0x70 0x00 0x00
				0x00 0x13 0x01 0x00 0x00 0x00 0x00 0x00 0x00
				0x00 0x3D 0x02 0x01 0x00 0x00 0x00 0x00 0x00
				0x00 0xED 0x0D 0x01 0x00 0x00 0x00 0x00 0x00
				0x00 0x23 0x02 0x00 0x00 0x00 0x00 0x00 0x0A
				0xff 0x00 0x00 0x00 0x00 0x00 0x00 0x00 0x00>;
			init_off = <0xff 0x00 0x00 0x00 0x00 0x00 0x00 0x00 0x00>;
		};
		extern_1{
			index = <1>;
			extern_name = "i2c_T5800Q";
			status = "disabled";
			type = <0>; /* 0=i2c, 1=spi, 2=mipi */
			i2c_address = <0x1c>; /* 7bit i2c address */
			i2c_bus = "i2c_bus_d";
		};
		extern_2{
			index = <2>;
			extern_name = "i2c_DLPC3439";
			status = "disabled";
			type = <0>; /* 0=i2c, 1=spi, 2=mipi */
			i2c_address = <0x1b>; /* 7bit i2c address */
			i2c_bus = "i2c_bus_a";
		};
	};

	backlight{
		compatible = "amlogic, backlight";
		dev_name = "backlight";
		status = "okay";
		key_valid = <0>;
		pinctrl-names = "pwm_on","pwm_vs_on",
				"pwm_combo_0_1_on",
				"pwm_combo_0_vs_1_on",
				"pwm_combo_0_on",
				"pwm_combo_0_vs_on",
				"pwm_combo_1_on";
		pinctrl-0 = <&bl_pwm_on_pins>;
		pinctrl-1 = <&bl_pwm_vs_on_pins>;
		pinctrl-2 = <&bl_pwm_combo_0_on_pins &bl_pwm_combo_1_on_pins>;
		pinctrl-3 = <&bl_pwm_combo_0_vs_on_pins &bl_pwm_combo_1_on_pins>;
		pinctrl-4 = <&bl_pwm_combo_0_on_pins>;
		pinctrl-5 = <&bl_pwm_combo_0_vs_on_pins>;
		pinctrl-6 = <&bl_pwm_combo_1_on_pins>;
		interrupts = <0 3 1 0 143 1>;

		/* power index:(point gpios_index, 0xff=invalid) */
		/* power value:(0=output low, 1=output high, 2=input) */
		/* power delay:(unit in ms) */
		bl-gpios = <&gpio_ao GPIOAO_4 GPIO_ACTIVE_HIGH
			&gpio GPIOY_13 GPIO_ACTIVE_HIGH
			&gpio GPIOY_8 GPIO_ACTIVE_HIGH>;
		bl_gpio_names = "GPIOAO_4","GPIOY_13","GPIOY_8";

		backlight_0{
			index = <0>;
			bl_name = "backlight_0";
			bl_level_default_uboot_kernel = <100 100>;
			bl_level_attr = <255 10 128 102>; /* max, min, mid, mid_mapping */

			bl_ctrl_method = <1>; /* 0=gpio, 1=pwm, 2=pwm_combo, 3=ldim, 4=extern */
			bl_power_attr = <0 0 1 200 200>; /* en_gpio_index, on_value, off_value, on_delay, off_delay */

			/* pwm_method: 0=negative, 1=positive */
			/* pwm_freq: pwm_vs: 1~4(vfreq multiple), other pwm: real freq(unit: Hz) */
			/* duty_max, duty_min: unit in % */
			bl_pwm_port = "PWM_B"; /* PWM_A, PWM_B, PWM_C, PWM_D, PWM_VS */
			bl_pwm_attr = <0 180 100 25>; /* pwm_method, pwm_freq, duty_max, duty_min */
			bl_pwm_power = <1 0 10 10>; /* pwm_gpio_index, pwm_gpio_off, pwm_on_delay, pwm_off_delay */
		};
		backlight_1{
			index = <1>;
			bl_name = "backlight_1";
			bl_level_default_uboot_kernel = <100 100>;
			bl_level_attr = <255 10 128 102>; /* max, min, mid, mid_mapping */

			bl_ctrl_method = <1>; /* 0=gpio, 1=pwm, 2=pwm_combo, 3=ldim, 4=extern */
			bl_power_attr = <0 1 0 200 200>; /* en_gpio_index, on_value, off_value, on_delay, off_delay */

			/* pwm_method: 0=negative, 1=positive */
			/* pwm_freq: pwm_vs: 1~4(vfreq multiple), other pwm: real freq(unit: Hz) */
			/* duty_max, duty_min: unit in % */
			bl_pwm_port = "PWM_VS"; /* PWM_A, PWM_B, PWM_C, PWM_D, PWM_VS */
			bl_pwm_attr = <1 2 100 25>; /* pwm_method, pwm_freq, duty_max, duty_min */
			bl_pwm_power = <1 0 10 10>; /* pwm_gpio_index, pwm_off_value, pwm_on_delay, pwm_off_delay */
		};
		backlight_2{
			index = <2>;
			bl_name = "backlight_2";
			bl_level_default_uboot_kernel = <100 100>;
			bl_level_attr = <255 10 128 102>; /* max, min, mid, mid_mapping */

			bl_ctrl_method = <3>; /* 0=gpio, 1=pwm, 2=pwm_combo, 3=ldim, 4=extern */
			bl_power_attr = <0 1 0 200 200>; /* en_gpio_index, on_value, off_value, on_delay, off_delay */

			bl_ldim_region_row_col = <1 8>;
			bl_ldim_mode = <1>; /* 1=single_side(top, bottom, left or right), 2=uniform(top/bottom, left/right) */
			bl_ldim_mapping = <0 1 2 3 4 5 6 7>;
			ldim_dev_index = <0>;
		};
		backlight_3{
			index = <3>;
			bl_name = "backlight_3";
			bl_level_default_uboot_kernel = <100 100>;
			bl_level_attr = <255 10 128 102>; /* max, min, mid, mid_mapping */

			bl_ctrl_method = <2>; /* 0=gpio, 1=pwm, 2=pwm_combo, 3=ldim, 4=extern */
			bl_power_attr = <0 1 0 200 200>; /* en_gpio_index, on_value, off_value, on_delay, off_delay */

			/* pwm_method: 0=negative, 1=positive */
			/* pwm_freq: pwm_vs: 1~4(vfreq multiple), other pwm: real freq(unit: Hz) */
			/* duty_max, duty_min: unit in % */
			bl_pwm_combo_level_mapping = <255 100 100 10>; /* level_max, level_min */
			bl_pwm_combo_port = "PWM_B","PWM_D"; /* PWM_A, PWM_B, PWM_C, PWM_D, PWM_VS */
			bl_pwm_combo_attr = <1 180 100 25
					     1 18000 100 20>; /* pwm_method, pwm_freq, duty_max, duty_min */
			bl_pwm_combo_power = <1 0 2 0 10 10>; /* pwm0_gpio_index, pwm0_gpio_off, pwm1_gpio_index, pwm1_gpio_off, pwm_on_delay, pwm_off_delay */
		};
		backlight_4{
			index = <4>;
			bl_name = "backlight_4";
			bl_level_default_uboot_kernel = <100 100>;
			bl_level_attr = <255 10 128 102>; /* max, min, mid, mid_mapping */

			bl_ctrl_method = <3>; /* 0=gpio, 1=pwm, 2=pwm_combo, 3=ldim, 4=extern */
			bl_power_attr = <0 1 0 200 200>; /* en_gpio_index, on_value, off_value, on_delay, off_delay */

			bl_ldim_region_row_col = <1 1>;
			bl_ldim_mode = <1>; /* 1=single_side(top, bottom, left or right), 2=uniform(top/bottom, left/right) */
			ldim_dev_index = <2>;
		};
		backlight_5{
			index = <5>;
			bl_name = "backlight_5";
			bl_level_default_uboot_kernel = <100 100>;
			bl_level_attr = <255 10 128 102>; /* max, min, mid, mid_mapping */

			bl_ctrl_method = <3>; /* 0=gpio, 1=pwm, 2=pwm_combo, 3=ldim, 4=extern */
			bl_power_attr = <0 1 0 200 200>; /* en_gpio_index, on_value, off_value, on_delay, off_delay */

			bl_ldim_region_row_col = <1 10>;
			bl_ldim_mode = <1>; /* 1=single_side(top, bottom, left or right), 2=uniform(top/bottom, left/right) */
			bl_ldim_mapping = <0 1 2 3 4 5 6 7 8 9>;
			ldim_dev_index = <1>;
		};
	};

	local_diming_device {
		compatible = "amlogic, ldim_dev";
		dev_name = "ldim_dev";
		status = "disabled";
		pinctrl-names = "ldim_pwm0","ldim_pwm1";
		pinctrl-0 = <&ldim_pwm0_pins>;
		pinctrl-1 = <&ldim_pwm1_pins>;

		ldim_dev-gpios = <&gpio GPIOX_9 GPIO_ACTIVE_HIGH
			&gpio GPIOX_11 GPIO_ACTIVE_HIGH
			&gpio GPIOY_4 GPIO_ACTIVE_HIGH>;
		ldim_dev_gpio_names = "GPIOX_9","GPIOX_11","GPIOY_4";

		ldim_dev_0 {
			index = <0>; /* 120mA */
			type = <1>; /* 0=normal,1=spi,2=i2c */
			ldim_dev_name = "iw7019";
			ldim_pwm_pinmux_sel = "ldim_pwm0";
			ldim_pwm_port = "none"; /* PWM_A, PWM_B, PWM_C, PWM_D, PWM_VS */
			ldim_pwm_attr = <1 2 50>; /* pol, freq(Hz for pwm, v-freq mulit for pwm_vs), duty(%) */
			spi_bus_num = <0>;
			spi_chip_select = <0>;
			spi_max_frequency = <400000>; /* unit: hz */
			spi_mode = <0>; /* mode: 0, 1, 2, 3 */
			spi_cs_delay = <10 100>; /* hold_high_delay, clk_cs_delay (unit: us) */

			en_gpio_on_off = <0 1 0>; /* ldim_dev-gpios index, on_level, off_level */
			lamp_err_gpio = <0xff>; /* ldim_dev-gpios index, 0xff=invalid */
			spi_write_check = <0>; /* 0=disable, 1=enable */

			dim_max_min = <0xfff 0x7f>; /* dim_max, dim_min */
			cmd_size = <4>;
			/* init: (type, data..., delay), must match cmd_size for every group */
			/*   type: 0x00=cmd, 0xff=ending*/
			/*   data: spi data, fill 0x0 for no use */
			/*   delay: unit ms */
			init_on = <
				/* step1: */
				0x00 0x01 0x08 0x00
				/* step2:disable ocp and otp */
				0x00 0x34 0x14 0x00
				0x00 0x10 0x53 0x00
				/* step3: */
				0x00 0x11 0x00 0x00
				0x00 0x12 0x02 0x00
				0x00 0x13 0x00 0x00
				0x00 0x14 0x40 0x00
				0x00 0x15 0x06 0x00
				0x00 0x16 0x00 0x00
				0x00 0x17 0x80 0x00
				0x00 0x18 0x0a 0x00
				0x00 0x19 0x00 0x00
				0x00 0x1a 0xc0 0x00
				0x00 0x1b 0x0e 0x00
				0x00 0x1c 0x00 0x00
				0x00 0x1d 0x00 0x00
				0x00 0x1e 0x50 0x00
				0x00 0x1f 0x00 0x00
				0x00 0x20 0x63 0x00
				0x00 0x21 0xff 0x00
				0x00 0x2a 0xff 0x00
				0x00 0x2b 0x41 0x00
				0x00 0x2c 0x28 0x00
				0x00 0x30 0xff 0x00
				0x00 0x31 0x00 0x00
				0x00 0x32 0x0f 0x00
				0x00 0x33 0x40 0x00
				0x00 0x34 0x40 0x00
				0x00 0x35 0x00 0x00
				0x00 0x3f 0xa3 0x00
				0x00 0x45 0x00 0x00
				0x00 0x47 0x04 0x00
				0x00 0x48 0x60 0x00
				0x00 0x4a 0x0d 0x00
				/* step4:set brightness */
				0x00 0x01 0x7f 0x00
				0x00 0x02 0xf7 0x00
				0x00 0x03 0xff 0x00
				0x00 0x04 0x7f 0x00
				0x00 0x05 0xf7 0x00
				0x00 0x06 0xff 0x00
				0x00 0x07 0x7f 0x00
				0x00 0x08 0xf7 0x00
				0x00 0x09 0xff 0x00
				0x00 0x0a 0x7f 0x00
				0x00 0x0b 0xf7 0x00
				0x00 0x0c 0xff 0x00
				/* step5: */
				0x00 0x00 0x09 0x00
				/* step6: */
				0x00 0x34 0x00 0x00
				0xff 0x00 0x00 0x00>;
		};
		ldim_dev_1 {
			index = <1>;
			type = <1>; /* 0=normal,1=spi,2=i2c */
			ldim_dev_name = "iw7027";
			ldim_pwm_pinmux_sel = "ldim_pwm0";
			ldim_pwm_port = "PWM_VS"; /* PWM_A, PWM_B, PWM_C, PWM_D, PWM_VS */
			ldim_pwm_attr = <1 2 50>; /* pol, freq(Hz for pwm, v-freq mulit for pwm_vs), duty(%) */
			spi_bus_num = <0>;
			spi_chip_select = <0>;
			spi_max_frequency = <400000>; /* unit: hz */
			spi_mode = <0>; /* mode: 0, 1, 2, 3 */
			spi_cs_delay = <10 100>; /* hold_high_delay, clk_cs_delay (unit: us) */

			en_gpio_on_off = <0 1 0>; /* ldim_dev-gpios index, on_level, off_level */
			lamp_err_gpio = <0xff>; /* ldim_dev-gpios index, 0xff=invalid */
			spi_write_check = <0>; /* 0=disable, 1=enable */

			dim_max_min = <0xfff 0x7f>; /* dim_max, dim_min */
			cmd_size = <4>;
			/* init: (type, data..., delay), must match cmd_size for every group */
			/*   type: 0x00=cmd, 0xff=ending*/
			/*   data: spi data, fill 0x0 for no use */
			/*   delay: unit ms */
			init_on = <
				0x00 0x23 0x03 0x00
				0x00 0x24 0xff 0x00
				0x00 0x25 0x00 0x00
				0x00 0x26 0x00 0x00
				0x00 0x27 0x60 0x00
				0x00 0x29 0x00 0x00
				0x00 0x2a 0x00 0x00
				/*0x00 0x2b 0x7f 0x00*/
				0x00 0x2c 0x73 0x00
				0x00 0x2d 0x37 0x00
				0x00 0x31 0x93 0x00
				0x00 0x32 0x0f 0x00
				0x00 0x33 0xff 0x00
				0x00 0x34 0xc8 0x00
				0x00 0x35 0xbf 0x00
				0xff 0x00 0x00 0x00>;
		};
		ldim_dev_2 {
			index = <2>;
			type = <0>; /* 0=normal,1=spi,2=i2c */
			ldim_dev_name = "ob3350";
			ldim_pwm_pinmux_sel = "ldim_pwm1";
			ldim_pwm_port = "PWM_B"; /* PWM_A, PWM_B, PWM_C, PWM_D, PWM_VS */
			ldim_pwm_attr = <0 200 50>; /* pol, freq(Hz for pwm, v-freq mulit for pwm_vs), duty(%) */
			dim_max_min = <100 20>; /* dim_max, dim_min */
			en_gpio_on_off = <2 0 1>; /* ldim_dev-gpios index, on_level, off_level */
		};
	};

	/* AUDIO MESON8 DEVICES */
	i2s_dai: I2S {
		#sound-dai-cells = <0>;
		resets = <
			&clock GCLK_IDX_AIU_AI_TOP_GLUE
			&clock GCLK_IDX_AUD_BUF_ABD
			&clock GCLK_IDX_AIU_I2S_OUT
			&clock GCLK_IDX_AIU_AMCLK_MEASURE
			&clock GCLK_IDX_AIU_AIFIFO2
			&clock GCLK_IDX_AIU_AUD_MIXER
			&clock GCLK_IDX_AIU_MIXER_REG
			&clock GCLK_IDX_AIU_ADC
			&clock GCLK_IDX_AIU_TOP_LEVEL
			&clock GCLK_IDX_AIU_AOCLK
			&clock GCLK_IDX_AUD_IN
		>;
		reset-names =
			"top_glue",
			"aud_buf",
			"i2s_out",
			"amclk_measure",
			"aififo2",
			"aud_mixer",
			"mixer_reg",
			"adc",
			"top_level",
			"aoclk",
			"aud_in";
		clocks = <&clock CLK_MPLL2>,
			<&clock CLK_AMCLK>;
		clock-names = "mpll2", "mclk";
		compatible = "amlogic, aml-i2s-dai";
	};
	spdif_dai: SPDIF {
		#sound-dai-cells = <0>;
		compatible = "amlogic, aml-spdif-dai";
		resets = <
			&clock GCLK_IDX_AIU_IEC958
			&clock GCLK_IDX_AIU_ICE958_AMCLK
		>;
		reset-names =
			"iec958",
			"iec958_amclk";
		clocks = <&clock CLK_MPLL1>,
			<&clock CLK_I958>,
			<&clock CLK_AMCLK>,
			<&clock CLK_SPDIF>,
			<&clock CLK_81>;
		clock-names = "mpll1", "i958", "mclk", "spdif", "clk_81";
	};
	pcm_dai: PCM {
		#sound-dai-cells = <0>;
		compatible = "amlogic, aml-pcm-dai";
		pinctrl-names = "aml_audio_btpcm";
		pinctrl-0 = <&audio_btpcm_pins>;
		clocks = <&clock CLK_MPLL0>,
			<&clock CLK_PCM_MCLK>,
			<&clock CLK_PCM_SCLK>;
		clock-names = "mpll0", "pcm_mclk", "pcm_sclk";
		pcm_mode = <1>;	/* 0=slave mode, 1=master mode */
	};
	i2s_plat: i2s_platform {
		compatible = "amlogic, aml-i2s";
		interrupts = <0 29 1>;
	};
	pcm_plat: pcm_platform {
		compatible = "amlogic, aml-pcm";
	};
	spdif_codec: spdif_codec {
		#sound-dai-cells = <0>;
		compatible = "amlogic, aml-spdif-codec";
		pinctrl-names = "aml_audio_spdif";
		pinctrl-0 = <&audio_spdif_pins>;
	};
	pcm_codec: pcm_codec {
		#sound-dai-cells = <0>;
		compatible = "amlogic, pcm2BT-codec";
	};
	/* endof AUDIO MESON8 DEVICES */

	/* AUDIO board specific */
	dummy_codec: dummy {
		#sound-dai-cells = <0>;
		compatible = "amlogic, aml_dummy_codec";
		status = "disable";
	};
	pmu4_codec: pmu4 {
		#sound-dai-cells = <0>;
		compatible = "amlogic, aml_pmu4_codec";
		status = "okay";
	};
	aml_g9tv_snd {
		compatible = "aml, aml_snd_g9tv";
		status = "okay";
		aml-sound-card,format = "i2s";
		aml_sound_card,name = "AML-G9TVAUDIO";
		pinctrl-names = "aml_snd_g9tv";
		pinctrl-0 = <&audio_pins>;
		mute_gpio-gpios = <&gpio GPIOZ_6 GPIO_ACTIVE_HIGH>;
		aux_dev = "tas5707";
		cpu_list = <&cpudai0 &cpudai1 &cpudai2>;
		codec_list = <&codec0 &codec1 &codec2>;
		plat_list = <&i2s_plat &i2s_plat &pcm_plat>;
		cpudai0: cpudai0 {
			sound-dai = <&i2s_dai>;
		};
		cpudai1: cpudai1 {
			sound-dai = <&spdif_dai>;
		};
		cpudai2: cpudai2 {
			sound-dai = <&pcm_dai>;
		};
		codec0: codec0 {
			sound-dai = <&pmu4_codec>;
			//sound-dai = <&dummy_codec>;
		};
		codec1: codec1 {
			sound-dai = <&spdif_codec>;
		};
		codec2: codec2 {
			sound-dai = <&pcm_codec>;
		};
		tas5707 {
			compatible = "amlogic, aml_tas5707_codec";
			codec_name = "tas5707";
			status = "okay";
			i2c_addr = <0x1B>;
			i2c_bus = "i2c_bus_b";
			master_vol = <150>;
			reset_pin = <&gpio GPIOX_19 GPIO_ACTIVE_LOW>;
			input_mux_reg_buf = /bits/ 8 <0x00 0x01 0x77 0x72>;/*AD mode*/
			eq_enable = <0>;
			drc_enable = <0>;
			table_0 = /bits/ 8 <
				0x00 0x80 0x00 0x00 0x00 0x00 0x00 0x00 0x00 0x00 0x00 0x00 0x00 0x00 0x00 0x00 0x00 0x00 0x00 0x00 /*0x29---ch1_bq[0]*/
				0x00 0x80 0x00 0x00 0x00 0x00 0x00 0x00 0x00 0x00 0x00 0x00 0x00 0x00 0x00 0x00 0x00 0x00 0x00 0x00 /*0x2A---ch1_bq[1]*/
				0x00 0x80 0x00 0x00 0x00 0x00 0x00 0x00 0x00 0x00 0x00 0x00 0x00 0x00 0x00 0x00 0x00 0x00 0x00 0x00 /*0x2B---ch1_bq[2]*/
				0x00 0x80 0x00 0x00 0x00 0x00 0x00 0x00 0x00 0x00 0x00 0x00 0x00 0x00 0x00 0x00 0x00 0x00 0x00 0x00 /*0x2C---ch1_bq[3]*/
				0x00 0x80 0x00 0x00 0x00 0x00 0x00 0x00 0x00 0x00 0x00 0x00 0x00 0x00 0x00 0x00 0x00 0x00 0x00 0x00 /*0x2D---ch1_bq[4]*/
				0x00 0x80 0x00 0x00 0x00 0x00 0x00 0x00 0x00 0x00 0x00 0x00 0x00 0x00 0x00 0x00 0x00 0x00 0x00 0x00 /*0x2E---ch1_bq[5]*/
				0x00 0x80 0x00 0x00 0x00 0x00 0x00 0x00 0x00 0x00 0x00 0x00 0x00 0x00 0x00 0x00 0x00 0x00 0x00 0x00 /*0x2F---ch1_bq[6]*/
				0x00 0x80 0x00 0x00 0x00 0x00 0x00 0x00 0x00 0x00 0x00 0x00 0x00 0x00 0x00 0x00 0x00 0x00 0x00 0x00 /*0x30---ch2_bq[0]*/
				0x00 0x80 0x00 0x00 0x00 0x00 0x00 0x00 0x00 0x00 0x00 0x00 0x00 0x00 0x00 0x00 0x00 0x00 0x00 0x00 /*0x31---ch2_bq[1]*/
				0x00 0x80 0x00 0x00 0x00 0x00 0x00 0x00 0x00 0x00 0x00 0x00 0x00 0x00 0x00 0x00 0x00 0x00 0x00 0x00 /*0x32---ch2_bq[2]*/
				0x00 0x80 0x00 0x00 0x00 0x00 0x00 0x00 0x00 0x00 0x00 0x00 0x00 0x00 0x00 0x00 0x00 0x00 0x00 0x00 /*0x33---ch2_bq[3]*/
				0x00 0x80 0x00 0x00 0x00 0x00 0x00 0x00 0x00 0x00 0x00 0x00 0x00 0x00 0x00 0x00 0x00 0x00 0x00 0x00 /*0x34---ch2_bq[4]*/
				0x00 0x80 0x00 0x00 0x00 0x00 0x00 0x00 0x00 0x00 0x00 0x00 0x00 0x00 0x00 0x00 0x00 0x00 0x00 0x00 /*0x35---ch2_bq[5]*/
				0x00 0x80 0x00 0x00 0x00 0x00 0x00 0x00 0x00 0x00 0x00 0x00 0x00 0x00 0x00 0x00 0x00 0x00 0x00 0x00 /*0x36---ch2_bq[6]*/
			>;
			wall_0 = /bits/ 8 <
				0x00 0x80 0x00 0x00 0x00 0x00 0x00 0x00 0x00 0x00 0x00 0x00 0x00 0x00 0x00 0x00 0x00 0x00 0x00 0x00 /*0x29---ch1_bq[0]*/
				0x00 0x80 0x00 0x00 0x00 0x00 0x00 0x00 0x00 0x00 0x00 0x00 0x00 0x00 0x00 0x00 0x00 0x00 0x00 0x00 /*0x2A---ch1_bq[1]*/
				0x00 0x80 0x00 0x00 0x00 0x00 0x00 0x00 0x00 0x00 0x00 0x00 0x00 0x00 0x00 0x00 0x00 0x00 0x00 0x00 /*0x2B---ch1_bq[2]*/
				0x00 0x80 0x00 0x00 0x00 0x00 0x00 0x00 0x00 0x00 0x00 0x00 0x00 0x00 0x00 0x00 0x00 0x00 0x00 0x00 /*0x2C---ch1_bq[3]*/
				0x00 0x80 0x00 0x00 0x00 0x00 0x00 0x00 0x00 0x00 0x00 0x00 0x00 0x00 0x00 0x00 0x00 0x00 0x00 0x00 /*0x2D---ch1_bq[4]*/
				0x00 0x80 0x00 0x00 0x00 0x00 0x00 0x00 0x00 0x00 0x00 0x00 0x00 0x00 0x00 0x00 0x00 0x00 0x00 0x00 /*0x2E---ch1_bq[5]*/
				0x00 0x80 0x00 0x00 0x00 0x00 0x00 0x00 0x00 0x00 0x00 0x00 0x00 0x00 0x00 0x00 0x00 0x00 0x00 0x00 /*0x2F---ch1_bq[6]*/
				0x00 0x80 0x00 0x00 0x00 0x00 0x00 0x00 0x00 0x00 0x00 0x00 0x00 0x00 0x00 0x00 0x00 0x00 0x00 0x00 /*0x30---ch2_bq[0]*/
				0x00 0x80 0x00 0x00 0x00 0x00 0x00 0x00 0x00 0x00 0x00 0x00 0x00 0x00 0x00 0x00 0x00 0x00 0x00 0x00 /*0x31---ch2_bq[1]*/
				0x00 0x80 0x00 0x00 0x00 0x00 0x00 0x00 0x00 0x00 0x00 0x00 0x00 0x00 0x00 0x00 0x00 0x00 0x00 0x00 /*0x32---ch2_bq[2]*/
				0x00 0x80 0x00 0x00 0x00 0x00 0x00 0x00 0x00 0x00 0x00 0x00 0x00 0x00 0x00 0x00 0x00 0x00 0x00 0x00 /*0x33---ch2_bq[3]*/
				0x00 0x80 0x00 0x00 0x00 0x00 0x00 0x00 0x00 0x00 0x00 0x00 0x00 0x00 0x00 0x00 0x00 0x00 0x00 0x00 /*0x34---ch2_bq[4]*/
				0x00 0x80 0x00 0x00 0x00 0x00 0x00 0x00 0x00 0x00 0x00 0x00 0x00 0x00 0x00 0x00 0x00 0x00 0x00 0x00 /*0x35---ch2_bq[5]*/
				0x00 0x80 0x00 0x00 0x00 0x00 0x00 0x00 0x00 0x00 0x00 0x00 0x00 0x00 0x00 0x00 0x00 0x00 0x00 0x00 /*0x36---ch2_bq[6]*/
			>;
			table_1 = /bits/ 8 <
				0x00 0x80 0x00 0x00 0x00 0x00 0x00 0x00 0x00 0x00 0x00 0x00 0x00 0x00 0x00 0x00 0x00 0x00 0x00 0x00 /*0x29---ch1_bq[0]*/
				0x00 0x80 0x00 0x00 0x00 0x00 0x00 0x00 0x00 0x00 0x00 0x00 0x00 0x00 0x00 0x00 0x00 0x00 0x00 0x00 /*0x2A---ch1_bq[1]*/
				0x00 0x80 0x00 0x00 0x00 0x00 0x00 0x00 0x00 0x00 0x00 0x00 0x00 0x00 0x00 0x00 0x00 0x00 0x00 0x00 /*0x2B---ch1_bq[2]*/
				0x00 0x80 0x00 0x00 0x00 0x00 0x00 0x00 0x00 0x00 0x00 0x00 0x00 0x00 0x00 0x00 0x00 0x00 0x00 0x00 /*0x2C---ch1_bq[3]*/
				0x00 0x80 0x00 0x00 0x00 0x00 0x00 0x00 0x00 0x00 0x00 0x00 0x00 0x00 0x00 0x00 0x00 0x00 0x00 0x00 /*0x2D---ch1_bq[4]*/
				0x00 0x80 0x00 0x00 0x00 0x00 0x00 0x00 0x00 0x00 0x00 0x00 0x00 0x00 0x00 0x00 0x00 0x00 0x00 0x00 /*0x2E---ch1_bq[5]*/
				0x00 0x80 0x00 0x00 0x00 0x00 0x00 0x00 0x00 0x00 0x00 0x00 0x00 0x00 0x00 0x00 0x00 0x00 0x00 0x00 /*0x2F---ch1_bq[6]*/
				0x00 0x80 0x00 0x00 0x00 0x00 0x00 0x00 0x00 0x00 0x00 0x00 0x00 0x00 0x00 0x00 0x00 0x00 0x00 0x00 /*0x30---ch2_bq[0]*/
				0x00 0x80 0x00 0x00 0x00 0x00 0x00 0x00 0x00 0x00 0x00 0x00 0x00 0x00 0x00 0x00 0x00 0x00 0x00 0x00 /*0x31---ch2_bq[1]*/
				0x00 0x80 0x00 0x00 0x00 0x00 0x00 0x00 0x00 0x00 0x00 0x00 0x00 0x00 0x00 0x00 0x00 0x00 0x00 0x00 /*0x32---ch2_bq[2]*/
				0x00 0x80 0x00 0x00 0x00 0x00 0x00 0x00 0x00 0x00 0x00 0x00 0x00 0x00 0x00 0x00 0x00 0x00 0x00 0x00 /*0x33---ch2_bq[3]*/
				0x00 0x80 0x00 0x00 0x00 0x00 0x00 0x00 0x00 0x00 0x00 0x00 0x00 0x00 0x00 0x00 0x00 0x00 0x00 0x00 /*0x34---ch2_bq[4]*/
				0x00 0x80 0x00 0x00 0x00 0x00 0x00 0x00 0x00 0x00 0x00 0x00 0x00 0x00 0x00 0x00 0x00 0x00 0x00 0x00 /*0x35---ch2_bq[5]*/
				0x00 0x80 0x00 0x00 0x00 0x00 0x00 0x00 0x00 0x00 0x00 0x00 0x00 0x00 0x00 0x00 0x00 0x00 0x00 0x00 /*0x36---ch2_bq[6]*/
			>;
			wall_1 = /bits/ 8 <
				0x00 0x80 0x00 0x00 0x00 0x00 0x00 0x00 0x00 0x00 0x00 0x00 0x00 0x00 0x00 0x00 0x00 0x00 0x00 0x00 /*0x29---ch1_bq[0]*/
				0x00 0x80 0x00 0x00 0x00 0x00 0x00 0x00 0x00 0x00 0x00 0x00 0x00 0x00 0x00 0x00 0x00 0x00 0x00 0x00 /*0x2A---ch1_bq[1]*/
				0x00 0x80 0x00 0x00 0x00 0x00 0x00 0x00 0x00 0x00 0x00 0x00 0x00 0x00 0x00 0x00 0x00 0x00 0x00 0x00 /*0x2B---ch1_bq[2]*/
				0x00 0x80 0x00 0x00 0x00 0x00 0x00 0x00 0x00 0x00 0x00 0x00 0x00 0x00 0x00 0x00 0x00 0x00 0x00 0x00 /*0x2C---ch1_bq[3]*/
				0x00 0x80 0x00 0x00 0x00 0x00 0x00 0x00 0x00 0x00 0x00 0x00 0x00 0x00 0x00 0x00 0x00 0x00 0x00 0x00 /*0x2D---ch1_bq[4]*/
				0x00 0x80 0x00 0x00 0x00 0x00 0x00 0x00 0x00 0x00 0x00 0x00 0x00 0x00 0x00 0x00 0x00 0x00 0x00 0x00 /*0x2E---ch1_bq[5]*/
				0x00 0x80 0x00 0x00 0x00 0x00 0x00 0x00 0x00 0x00 0x00 0x00 0x00 0x00 0x00 0x00 0x00 0x00 0x00 0x00 /*0x2F---ch1_bq[6]*/
				0x00 0x80 0x00 0x00 0x00 0x00 0x00 0x00 0x00 0x00 0x00 0x00 0x00 0x00 0x00 0x00 0x00 0x00 0x00 0x00 /*0x30---ch2_bq[0]*/
				0x00 0x80 0x00 0x00 0x00 0x00 0x00 0x00 0x00 0x00 0x00 0x00 0x00 0x00 0x00 0x00 0x00 0x00 0x00 0x00 /*0x31---ch2_bq[1]*/
				0x00 0x80 0x00 0x00 0x00 0x00 0x00 0x00 0x00 0x00 0x00 0x00 0x00 0x00 0x00 0x00 0x00 0x00 0x00 0x00 /*0x32---ch2_bq[2]*/
				0x00 0x80 0x00 0x00 0x00 0x00 0x00 0x00 0x00 0x00 0x00 0x00 0x00 0x00 0x00 0x00 0x00 0x00 0x00 0x00 /*0x33---ch2_bq[3]*/
				0x00 0x80 0x00 0x00 0x00 0x00 0x00 0x00 0x00 0x00 0x00 0x00 0x00 0x00 0x00 0x00 0x00 0x00 0x00 0x00 /*0x34---ch2_bq[4]*/
				0x00 0x80 0x00 0x00 0x00 0x00 0x00 0x00 0x00 0x00 0x00 0x00 0x00 0x00 0x00 0x00 0x00 0x00 0x00 0x00 /*0x35---ch2_bq[5]*/
				0x00 0x80 0x00 0x00 0x00 0x00 0x00 0x00 0x00 0x00 0x00 0x00 0x00 0x00 0x00 0x00 0x00 0x00 0x00 0x00 /*0x36---ch2_bq[6]*/
			>;
			drc1_tko_table_0 = /bits/ 8 <
				0xFD 0xA2 0x14 0x90 /*0x40---drc1_t*/
				0x03 0x84 0x21 0x09 /*0x41---drc1_k*/
				0x00 0x08 0x42 0x10 /*0x42---drc1_o*/
			>;
			drc1_table_0 = /bits/ 8 <
				0x00 0x08 0x00 0x00 0x00 0x00 0x00 0x00 /*0x3A---drc1_ae*/
				0x00 0x08 0x00 0x00 0x00 0x00 0x00 0x00 /*0x3B---drc1_aa*/
				0x00 0x08 0x00 0x00 0x00 0x00 0x00 0x00 /*0x3C---drc1_ad*/
			>;
			drc1_tko_table_1 = /bits/ 8 <
				0xFD 0xA2 0x14 0x90 /*0x40---drc1_t*/
				0x03 0x84 0x21 0x09 /*0x41---drc1_k*/
				0x00 0x08 0x42 0x10 /*0x42---drc1_o*/
			>;
			drc1_table_1 = /bits/ 8 <
				0x00 0x08 0x00 0x00 0x00 0x00 0x00 0x00 /*0x3A---drc1_ae*/
				0x00 0x08 0x00 0x00 0x00 0x00 0x00 0x00 /*0x3B---drc1_aa*/
				0x00 0x08 0x00 0x00 0x00 0x00 0x00 0x00 /*0x3C---drc1_ad*/
			>;
		};
 	};
	amaudio2 {
		compatible = "amlogic, aml_amaudio2";
		status = "okay";
		interrupts = <0 48 1>;
 	};

	ethmac: ethernet@0xc9410000{
		compatible = "amlogic, gxbb-rmii-dwmac";
		reg = <0x0 0xc9410000 0x0 0x10000
			0x0 0xc8834540 0x0 0x8>;
		interrupts = <0 8 1>;
		phy-mode= "rmii";
		pinctrl-names = "eth_pins";
		pinctrl-0 = <&eth_pins>;
		#rst_pin-gpios = <&gpio GPIOZ_14 0>;
		mc_val = <0x1800>;
		resets = <&clock GCLK_IDX_ETHERNET>;
		reset-names = "ethpower";
		interrupt-names = "macirq";
		clocks = <&clock CLK_81>;
		clock-names = "ethclk81";
	};

	pwm {
		compatible = "amlogic, meson-pwm";
		status = "okay";
		pwm-outputs 	= <PWM_A>,<PWM_B>,<PWM_C>,<PWM_D>,
			      	  <PWM_E>,<PWM_F>,<PWM_AO_A>,<PWM_AO_B>;
		pwm-outputs-new = <PWM_A>,<PWM_B>,<PWM_C>,<PWM_D>,
				  <PWM_E>,<PWM_F>,<PWM_AO_A>,<PWM_AO_B>,
			          <PWM_A2>,<PWM_B2>,<PWM_C2>,<PWM_D2>,
			          <PWM_E2>,<PWM_F2>,<PWM_AO_A2>,<PWM_AO_B2>;
		reg = <0x0 0xc1108550 0x0 0x30>,
		      <0x0 0xc8100550  0x0 0x10>;
		clocks = <&clock CLK_XTAL>,
			 <&clock CLK_VID_PLL>,
			 <&clock CLK_FPLL_DIV4>,
			 <&clock CLK_FPLL_DIV3>;
		clock-names = "xtal",
			      "vid_pll_clk",
			      "fclk_div4",
			      "fclk_div3";
		clock-select 	 = <XTAL_CLK>,<XTAL_CLK>,<XTAL_CLK>,<XTAL_CLK>,
			       	   <XTAL_CLK>,<XTAL_CLK>,<XTAL_CLK>,<XTAL_CLK>;
		clock-select-new = <XTAL_CLK>,<XTAL_CLK>,<XTAL_CLK>,<XTAL_CLK>,
		                   <XTAL_CLK>,<XTAL_CLK>,<XTAL_CLK>,<XTAL_CLK>,
		                   <XTAL_CLK>,<XTAL_CLK>,<XTAL_CLK>,<XTAL_CLK>,
		                   <XTAL_CLK>,<XTAL_CLK>,<XTAL_CLK>,<XTAL_CLK>;
		                   /*all channels use the default clock source XTAL_CLK*/
		                   /*and you can shoose it in file dt-bindings/pwm/meson.h*/
	};

	aml_sensor0: aml-sensor@0 {
		compatible = "amlogic, aml-thermal";
		device_name = "thermal";
		#thermal-sensor-cells = <1>;
		cooling_devices {
			cpufreq_cool_cluster0 {
				min_state = <1000000>;
				dyn_coeff = <140>;
				cluster_id = <0>;
				node_name = "cpus";
				device_type = "cpufreq";
			};
			cpucore_cool_cluster0 {
				min_state = <1>;
				dyn_coeff = <0>;
				cluster_id = <0>;
				node_name = "cpu_core_cluster0";
				device_type = "cpucore";
			};
			gpufreq_cool {
				min_state = <400>;
				dyn_coeff = <437>;
				cluster_id = <0>;
				node_name = "t83x";
				device_type = "gpufreq";
			};
			gpucore_cool {
				min_state = <1>;
				dyn_coeff = <0>;
				cluster_id = <0>;
				node_name = "thermal_gpu_cores";
				device_type = "gpucore";
			};
		};
		cpu_cluster0:cpu_core_cluster0 {
			#cooling-cells = <2>; /* min followed by max */
		};
		gpucore:thermal_gpu_cores {
			#cooling-cells = <2>; /* min followed by max */
		};
	};
	thermal-zones {
		soc_thermal {
			polling-delay = <1000>;
			polling-delay-passive = <100>;
			sustainable-power = <1800>;

			thermal-sensors = <&aml_sensor0 3>;

			trips {
				switch_on: trip-point@0 {
					temperature = <70000>;
					hysteresis = <1000>;
					type = "passive";
				};
				control: trip-point@1 {
					temperature = <80000>;
					hysteresis = <1000>;
					type = "passive";
				};
				hot: trip-point@2 {
					temperature = <85000>;
					hysteresis = <5000>;
					type = "hot";
				};
				critical: trip-point@3 {
					temperature = <260000>;
					hysteresis = <1000>;
					type = "critical";
				};
			};

			cooling-maps {
				cpufreq_cooling_map {
					trip = <&control>;
					cooling-device = <&cpus 0 4>;
					contribution = <1024>;
				};
				cpucore_cooling_map {
					trip = <&control>;
					cooling-device = <&cpu_cluster0 0 3>;
					contribution = <1024>;
				};
				gpufreq_cooling_map {
					trip = <&control>;
					cooling-device = <&t83x_gpu 0 4>;
					contribution = <1024>;
				};
				gpucore_cooling_map {
					trip = <&control>;
					cooling-device = <&gpucore 0 2>;
					contribution = <1024>;
				};
			};
		};
	};

	adc_keypad{
			compatible = "amlogic, adc_keypad";
			status = "okay";
			key_name = "left", "right","up", "down", "enter";
			key_num = <5>;
			key_code = <106 105 103 108 28>;
			key_chan = <2 2 3 3 3>;
			key_val = <516 253 516 750 0>; //voltage=0/252/478/692/824mV, val=voltage/1800mV*1023
			key_tolerance = <40 40 40 40 40>;
		};

	/* END OF AUDIO board specific */
};

	&i2c_ao {
		status = "disabled";
		pinctrl-names="default";
		pinctrl-0=<&ao_i2c_master>;
	};

	&i2c_a {
		status = "okay";
		pinctrl-names="default";
		pinctrl-0=<&a_i2c_master>;
	};

	&i2c_b {
		status = "okay";
		pinctrl-names="default";
		pinctrl-0=<&b_i2c_master_pin1>;
	};
	&i2c_c {
		status = "disabled";
		pinctrl-names="default";
		pinctrl-0=<&c_i2c_master>;
	};
	&i2c_d {
		status = "disabled";
		pinctrl-names="default";
		pinctrl-0=<&d_i2c_master>;

		at24 {
			/*compatible = "at24,24c32";*/
			dev_name = "at24";
			reg = <0x50>;
			status = "disabled";
			pagesize = <8>;
			write_ops_interval= <10>;/*Write operation interval  at24c32 at24c64 is 10ms  at24c128 is 5ms in spec*/
			wp_gpios = <&gpio  GPIOY_7  GPIO_ACTIVE_HIGH>;
			write_gpio_port_status = <0>;
		};
	};
&pinmux {
	audio_pins:audio_pin{
		amlogic,setmask=<8 0x7E0>;
		amlogic,clrmask=<8 0x3800>;
		amlogic,pins = "GPIOZ_0","GPIOZ_1","GPIOZ_2","GPIOZ_3","GPIOZ_4","GPIOZ_5";
	};

	audio_spdif_pins:audio_pin1{
		amlogic,setmask=<8 0x4>;
		amlogic,clrmask=<8 0x10
				 7 0x4000>;
		amlogic,pins = "GPIOH_10";
	};

	audio_btpcm_pins:audio_btpcm_pins{
		/* BT PCM PINMUX SETTING*/
		amlogic,setmask=<1 0x3c0000>;
		amlogic,clrmask=<1 0x3C000000>;
		amlogic,pins ="GPIOX_4", "GPIOX_5", "GPIOX_6", "GPIOX_7";
	};

	eth_pins: eth_pins{
		amlogic,setmask =<8 0x19cf8000>;
		amlogic,clrmask =<8 0x20000000>,
			<9 0x1806>;
		amlogic,pins="GPIOZ_7","GPIOZ_8","GPIOZ_9",
			"GPIOZ_10","GPIOZ_11","GPIOZ_14","GPIOZ_15",
			"GPIOZ_16","GPIOZ_19","GPIOZ_20";
	};

	ldim_pwm0_pins:ldim_pwm0_pin {
		amlogic,setmask = <2 0x00200000>;
		amlogic,clrmask = <0 0x00900000
				   1 0x00000008
				   2 0x00180400
					 3 0x20000000>;
		amlogic,pins = "GPIOX_10";
	};
	ldim_pwm1_pins:ldim_pwm1_pin {
		amlogic,setmask = <10 0x00800000>;
		amlogic,clrmask = <10 0x0100a000>;
		amlogic,pins = "GPIOY_13";
	};

	bl_pwm_on_pins:bl_pwm_on_pin {
		amlogic,setmask = <10 0x00800000>;
		amlogic,clrmask = <10 0x0100a000>;
		amlogic,pins = "GPIOY_13";
	};
	bl_pwm_vs_on_pins:bl_pwm_vs_on_pin {
		amlogic,setmask = <10 0x01000000>;
		amlogic,clrmask = <10 0x0080a000>;
		amlogic,pins = "GPIOY_13";
	};
	bl_pwm_combo_0_on_pins:bl_pwm_combo_0_on_pin {
		amlogic,setmask = <10 0x00800000>;
		amlogic,clrmask = <10 0x0100a000>;
		amlogic,pins = "GPIOY_13";
	};
	bl_pwm_combo_1_on_pins:bl_pwm_combo_1_on_pin {
		amlogic,setmask = <10 0x00040000>;
		amlogic,clrmask = <4 0x29001008>;
		amlogic,pins = "GPIOY_8";
	};
	bl_pwm_combo_0_vs_on_pins:bl_pwm_combo_0_vs_on_pin {
		amlogic,setmask = <10 0x01000000>;
		amlogic,clrmask = <10 0x0080a000>;
		amlogic,pins = "GPIOY_13";
	};
	hdmirx_pins: hdmirx_pins {
                amlogic,setmask = <6  0x3def780>;
                amlogic,clrmask = <6  0x04210800>,
                                  <10 0x0000001e>;
                amlogic,pins = "GPIOW_6","GPIOW_8",
                        "GPIOW_10","GPIOW_12",
                        "GPIOW_14","GPIOW_16",
                        "GPIOW_17","GPIOW_18","GPIOW_19","GPIOW_20";
        };
	hdmirx_init_pin:hdmirx_init_pin {
		        amlogic,setmask = <6  0x3def780>;
                amlogic,clrmask = <6  0x04210800>,
                                  <10 0x0000001e>;
                amlogic,pins = "GPIOW_7";
	};
	hu_det_none: hu_det_none {
		amlogic,setmask = <6  0x3def780>,
			<AO 0x3>;
		amlogic,clrmask = <6  0x04210800>,
			<10 0x0000001e>;
		amlogic,pins = "GPIOW_5";
	};
	cha_uart_in: cha_uart_in {
		amlogic,setmask = <6  0x00000800>,
			<10  0x00000002>;
		amlogic,clrmask = <6  0x00000600>,
			<AO 0x33>;
		amlogic,pins = "GPIOW_7","GPIOW_8";
	};
	chb_uart_in: chb_uart_in {
		amlogic,setmask = <6  0x00010000>,
			<10  0x00000004>;
		amlogic,clrmask = <6  0x0000c000>,
			<AO 0x33>;
		amlogic,pins = "GPIOW_11","GPIOW_12";
	};
	chc_uart_in: chc_uart_in {
		amlogic,setmask = <6  0x00200000>,
			<10  0x00000008>;
		amlogic,clrmask = <6  0x00180000>,
			<AO 0x33>;
		amlogic,pins = "GPIOW_15","GPIOW_16";
	};
	u_ch1_in:u_ch1_in {
		amlogic,clrmask = <AO 0x33>,
						  <6  0x600>;
		amlogic,setmask = <6  0x800>,
						  <10 0x2>;
		amlogic,pins = "GPIOW_7";
	};
	u_ch2_in:u_ch2_in {
		amlogic,clrmask = <AO 0x33>,
						  <6  0xC000>;
		amlogic,setmask = <6  0x10000>,
						  <10 0x4>;
		amlogic,pins = "GPIOW_11";
	};
	u_ch3_in:u_ch3_in {
		amlogic,clrmask = <AO 0x33>,
						  <6  0x180000>;
		amlogic,setmask = <6  0x200000>,
						  <10 0x8>;
		amlogic,pins = "GPIOW_15";
	};
	hu_hpd1_pinmux:hu_hpd1_pinmux {
		amlogic,setmask=<6 0x80>;
		amlogic,pins = "GPIOW_5";
	};
	hu_hpd2_pinmux:hu_hpd2_pinmux {
		amlogic,setmask=<6 0x1000>;
		amlogic,pins = "GPIOW_9";
	};
	hu_hpd3_pinmux:hu_hpd3_pinmux {
		amlogic,setmask=<6 0x20000>;
		amlogic,pins = "GPIOW_13";
	};
	hu_hpd1_gpio:hu_hpd1_gpio {
		amlogic,setmask=<AO 0x3>;
		amlogic,clrmask=<6 0x80>;
		amlogic,pins = "GPIOW_5";
		amlogic,enable-output=<1>;
		amlogic,pullupen=<1>;
		amlogic,pullup=<0>;
	};
	hu_hpd2_gpio:hu_hpd2_gpio {
		amlogic,setmask=<AO 0x3>;
		amlogic,clrmask=<6 0x1000>;
		amlogic,pins = "GPIOW_9";
		amlogic,enable-output=<1>;
		amlogic,pullupen=<1>;
		amlogic,pullup=<0>;
	};
	hu_hpd3_gpio:hu_hpd3_gpio {
		amlogic,setmask=<AO 0x3>;
		amlogic,clrmask=<6 0x20000>;
		amlogic,pins = "GPIOW_13";
		amlogic,enable-output=<1>;
		amlogic,pullupen=<1>;
		amlogic,pullup=<0>;
	};
	hu_hpds_gpio:hu_hpds_gpio {
		amlogic,setmask=<AO 0x3>;
		amlogic,clrmask=<6 0x21080>;
		amlogic,pins = "GPIOW_5","GPIOW_9","GPIOW_13";
		amlogic,enable-output=<1>;
		amlogic,pullupen=<1>;
		amlogic,pullup=<0>;
	};
	hu_uart_init:hu_uart_init {
		amlogic,setmask=<AO 0x3>;
		amlogic,pins = "GPIOW_5";
	};
	avin_gpio_disable_pull:avin_gpio_disable_pull{
		amlogic,pins = "GPIOW_3","GPIOW_4";
		amlogic,enable-output=<1>;
		amlogic,pullupen=<0>;
	};
	/* pwm_ao_a */
	pwm_ao_a_pins:pwm_ao_a_pins {
		amlogic,setmask=<AO 0x80000>;
		amlogic,clrmask=<AO 0x100000>;
		amlogic,pins="GPIOAO_11";
	};
};


&efuse {
	status = "okay";
};
&audio_data{
	status = "okay";
};

	&spicc{
		status = "okay";
		pinctrl-names = "spicc_pulldown","spicc_pullup";
		pinctrl-0 = <&spicc_pulldown_h6h7h8 &spicc_pins_h6h7h8>;
		pinctrl-1 = <&spicc_pullup_h6h7h8 &spicc_pins_h6h7h8>;
		num_chipselect = <1>;
		cs-gpios = <&gpio GPIOH_9 GPIO_ACTIVE_HIGH>;
		#address-cells = <1>;
		#size-cells = <0>;
	};
